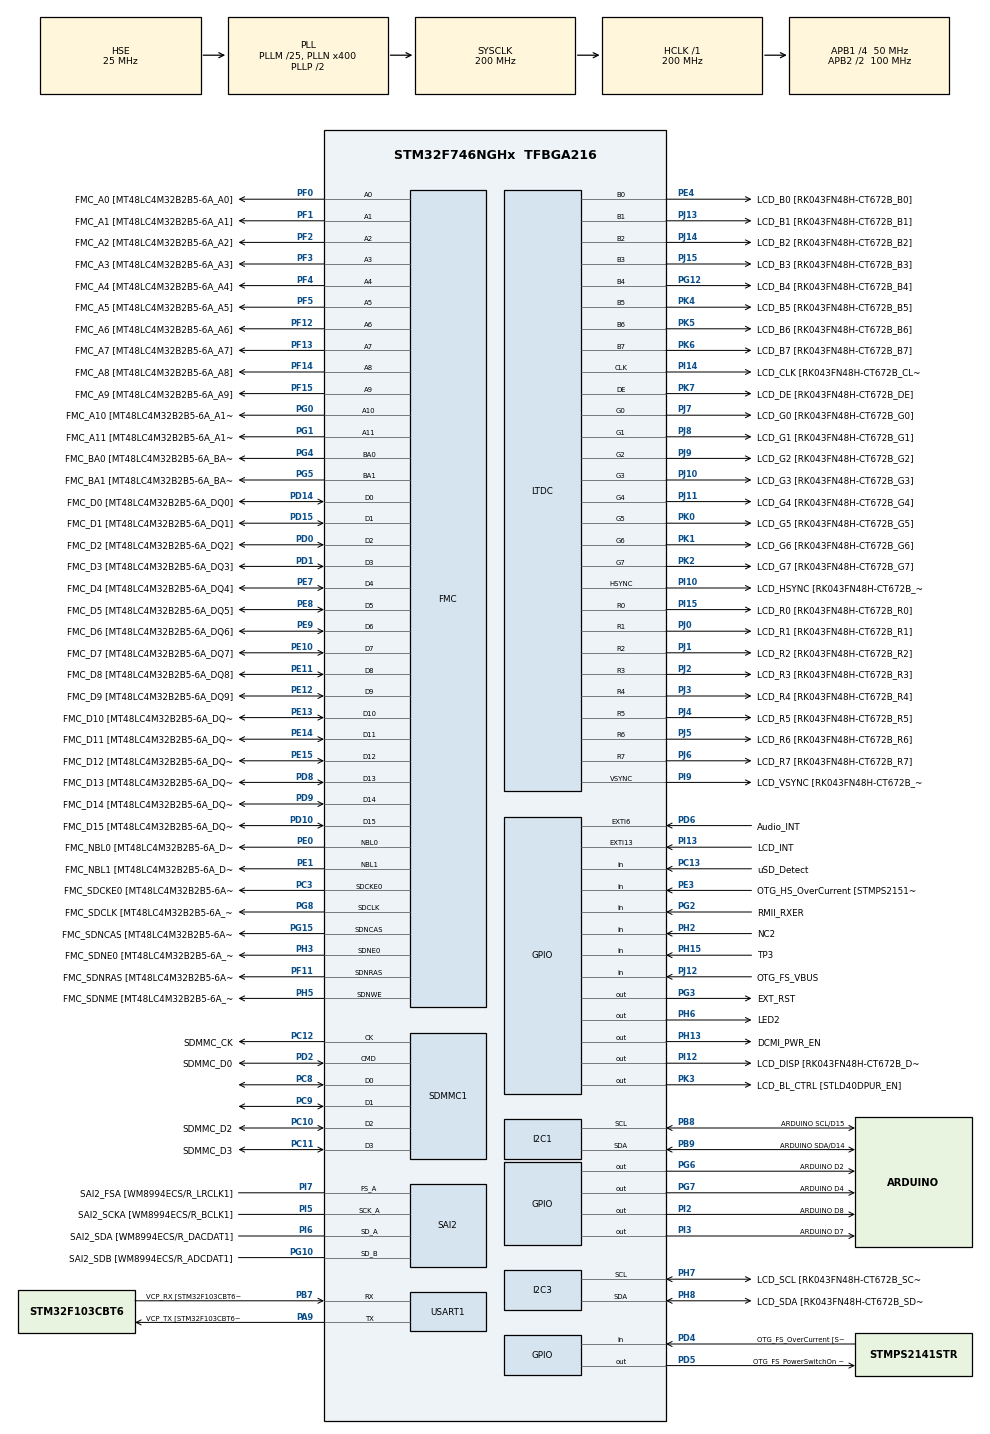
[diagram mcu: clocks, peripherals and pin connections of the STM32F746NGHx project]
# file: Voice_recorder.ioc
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PD12.GPIO_Label=QSPI_D1 [N25Q128A13EF840E_DQ1]
SH.FMC_A0.0=FMC_A0,12b-sda1
FATFS0.BSP.api=Unknown
PH15.GPIO_Label=TP3
NVIC.TIM6_DAC_IRQn=true\:0\:0\:false\:false\:true\:false\:false\:true
PG8.Signal=FMC_SDCLK
PG0.Signal=FMC_A10
PI15.GPIO_Label=LCD_R0 [RK043FN48H-CT672B_R0]
PK1.Signal=LTDC_G6
SH.FMC_D5_DA5.0=FMC_D5,sd-16b-d1
PF10.GPIO_PuPd=GPIO_NOPULL
SH.FMC_D9_DA9.0=FMC_D9,sd-16b-d1
PG15.GPIO_Label=FMC_SDNCAS [MT48LC4M32B2B5-6A_CAS]
PF7.Signal=ADC3_IN5
RCC.PLL48CLockSelection=RCC_CLK48SOURCE_PLLSAIP
SH.FMC_SDNWE.0=FMC_SDNWE,12b-sda1
PH9.Signal=DCMI_D0
SH.FMC_D11_DA11.0=FMC_D11,sd-16b-d1
PJ5.Mode=RGB888
RCC.APB2TimFreq_Value=200000000
PB6.Signal=QUADSPI_BK1_NCS
PC7.Signal=USART6_RX
PD0.Signal=FMC_D2_DA2
PD8.Signal=FMC_D13_DA13
PE1.Signal=FMC_NBL1
FATFS0.BSP.ip=GPIO
Dma.SAI2_B.3.Mode=DMA_CIRCULAR
PF1.GPIO_Label=FMC_A1 [MT48LC4M32B2B5-6A_A1]
PI4.GPIO_Label=SAI2_MCLKA [WM8994ECS/R_MCLK1]
PK4.GPIO_Label=LCD_B5 [RK043FN48H-CT672B_B5]
PD1.GPIO_Label=FMC_D3 [MT48LC4M32B2B5-6A_DQ3]
PB12.GPIO_Label=ULPI_D5 [USB3320C-EZK_D5]
PJ14.Mode=RGB888
PF12.GPIO_Label=FMC_A6 [MT48LC4M32B2B5-6A_A6]
LTDC.PixelFormat_L0=LTDC_PIXEL_FORMAT_RGB565
LTDC.PixelFormat_L1=LTDC_PIXEL_FORMAT_RGB565
SAI2.Instance-SAI_B_SyncSlave=SAI$Index_Block_B
PC4.GPIO_Label=RMII_RXD0 [LAN8742A-CZ-TR_RXD0]
PE9.Signal=FMC_D6_DA6
SH.FMC_A2.0=FMC_A2,12b-sda1
PB1.GPIO_Label=ULPI_D2 [USB3320C-EZK_D2]
PE4.GPIO_Label=LCD_B0 [RK043FN48H-CT672B_B0]
PG4.GPIO_Label=FMC_BA0 [MT48LC4M32B2B5-6A_BA0]
PC9.Mode=SD_4_bits_Wide_bus
PA8.Signal=S_TIM1_CH1
SH.FMC_D1_DA1.0=FMC_D1,sd-16b-d1
VP_FREERTOS_VS_CMSIS_V1.Mode=CMSIS_V1
LTDC.HSync=41
PJ14.Signal=LTDC_B2
Dma.SAI2_A.2.Priority=DMA_PRIORITY_LOW
PB9.Signal=I2C1_SDA
Mcu.Package=TFBGA216
PB1.Signal=USB_OTG_HS_ULPI_D2
PB14.GPIO_PuPd=GPIO_NOPULL
Dma.SAI2_B.3.Instance=DMA2_Stream7
NVIC.TimeBase=TIM6_DAC_IRQn
PD12.Signal=QUADSPI_BK1_IO1
NVIC.TimeBaseIP=TIM6
PB9.GPIO_PuPd=GPIO_NOPULL
PA10.Signal=USB_OTG_FS_ID
PE12.GPIO_Label=FMC_D9 [MT48LC4M32B2B5-6A_DQ9]
PC11.Mode=SD_4_bits_Wide_bus
RCC.APB2CLKDivider=RCC_HCLK_DIV2
PI7.Mode=SAI_A_Master
LTDC.VSync=10
RCC.APB1TimFreq_Value=100000000
PC14/OSC32_IN.GPIO_Label=RCC_OSC32_IN
PJ13.Mode=RGB888
PH8.Mode=I2C
PF9.GPIO_PuPd=GPIO_NOPULL
Dma.SDMMC1_RX.0.Mode=DMA_PFCTRL
PA4.GPIO_Label=DCMI_HSYNC
PA8.GPIO_Speed=GPIO_SPEED_FREQ_LOW
PD15.Signal=FMC_D1_DA1
PJ1.GPIO_Label=LCD_R2 [RK043FN48H-CT672B_R2]
PG12.Signal=LTDC_B4
Dma.SAI2_B.3.FIFOMode=DMA_FIFOMODE_DISABLE
FATFS0.BSP.STBoard=false
PK4.Signal=LTDC_B5
SH.FMC_A4.0=FMC_A4,12b-sda1
FREERTOS.Tasks01=defaultTask,-3,128,StartDefaultTask,Default,NULL,Dynamic,NULL,NULL;SD,0,20000,SDTask,Default,NULL,Dynamic,NULL,NULL;Audio,0,2048,AudioTask,Default,NULL,Dynamic,NULL,NULL;input,0,1024,InputTask,Default,NULL,Dynamic,NULL,NULL
Dma.SDMMC1_RX.0.PeriphInc=DMA_PINC_DISABLE
PH13.Signal=GPIO_Output
PI13.GPIO_ModeDefaultEXTI=GPIO_MODE_EVT_RISING
PG5.Signal=FMC_A15_BA1
PC13.Signal=GPIO_Input
SH.FMC_D10_DA10.0=FMC_D10,sd-16b-d1
FATFS0.BSP.mode=Input
FREERTOS.INCLUDE_vTaskDelayUntil=1
PD3.Signal=DCMI_D5
PI10.Mode=RGB888
PC2.Signal=USB_OTG_HS_ULPI_DIR
PI12.Signal=GPIO_Output
LTDC.ImageWidth_L1=480
Dma.SAI2_A.2.MemInc=DMA_MINC_ENABLE
PJ11.Signal=LTDC_G4
RCC.PLLSAIRDiv=RCC_PLLSAIDIVR_8
PF8.GPIO_Label=ARDUINO A3
LTDC.ImageWidth_L0=480
PD10.Signal=FMC_D15_DA15
PJ6.Mode=RGB888
PB8.GPIO_Label=ARDUINO SCL/D15
PJ8.GPIO_Label=LCD_G1 [RK043FN48H-CT672B_G1]
PJ3.Signal=LTDC_R4
PI8.GPIO_Label=NC1 [TP2]
PA8.GPIO_Label=ARDUINO PWM/D10
CORTEX_M7.ART_ACCLERATOR_ENABLE=1
PE8.GPIO_Label=FMC_D5 [MT48LC4M32B2B5-6A_DQ5]
PH11.GPIO_Label=DCMI_D2
PI6.Mode=SAI_A_Master
NVIC.DMA2_Stream6_IRQn=true\:5\:0\:false\:false\:true\:true\:false\:true
PJ11.GPIO_Label=LCD_G4 [RK043FN48H-CT672B_G4]
PB14.Signal=SPI2_MISO
PA5.Signal=USB_OTG_HS_ULPI_CK
PC12.Mode=SD_4_bits_Wide_bus
PF10.GPIO_Mode=GPIO_MODE_ANALOG
PJ4.GPIO_Label=LCD_R5 [RK043FN48H-CT672B_R5]
PE1.GPIO_Label=FMC_NBL1 [MT48LC4M32B2B5-6A_DQM1]
PK7.GPIO_Label=LCD_DE [RK043FN48H-CT672B_DE]
PI7.Signal=SAI2_FS_A
SH.FMC_A6.0=FMC_A6,12b-sda1
PE14.Signal=FMC_D11_DA11
LTDC.Blue_L1=0
LTDC.Blue_L0=255
PB4.GPIO_Label=ARDUINO PWM/D3
PB15.GPIO_Label=ARDUINO MOSI/PWM/D11
PG7.GPIO_Label=ARDUINO D4
PI2.Signal=GPIO_Output
PF4.GPIO_Label=FMC_A4 [MT48LC4M32B2B5-6A_A4]
PA1.GPIO_Label=RMII_REF_CLK [LAN8742A-CZ-TR_REFCLK0]
PF13.Signal=FMC_A7
Dma.SAI2_A.2.PeriphInc=DMA_PINC_DISABLE
PA0/WKUP.GPIO_PuPd=GPIO_NOPULL
PJ15.GPIO_Label=LCD_B3 [RK043FN48H-CT672B_B3]
NVIC.DMA2_Stream4_IRQn=true\:5\:0\:false\:false\:true\:true\:false\:true
PC7.GPIO_Label=ARDUINO RX/D0
PC8.Mode=SD_4_bits_Wide_bus
PJ15.Mode=RGB888
PA5.GPIO_Label=ULPI_CLK [USB3320C-EZK_CLKOUT]
PK4.Mode=RGB888
PC12.GPIO_Label=SDMMC_CK
PE5.GPIO_Label=DCMI_D6
Dma.SDMMC1_TX.1.PeriphDataAlignment=DMA_PDATAALIGN_WORD
PJ8.Signal=LTDC_G1
PJ0.GPIO_Label=LCD_R1 [RK043FN48H-CT672B_R1]
ProjectManager.HeapSize=0x400
PH6.Signal=GPIO_Output
NVIC.PriorityGroup=NVIC_PRIORITYGROUP_4
PF0.GPIO_Label=FMC_A0 [MT48LC4M32B2B5-6A_A0]
PI1.GPIO_Mode=GPIO_MODE_AF_PP
PE3.Signal=GPIO_Input
PJ4.Mode=RGB888
PC15/OSC32_OUT.Signal=RCC_OSC32_OUT
PF4.Signal=FMC_A4
PD2.Signal=SDMMC1_CMD
FATFS0.BSP.name=Detect_SDIO
PI1.GPIO_Label=ARDUINO SCK/D13
Mcu.Family=STM32F7
LTDC.BlendingFactor1_L1=LTDC_BLENDING_FACTOR1_PAxCA
LTDC.BlendingFactor1_L0=LTDC_BLENDING_FACTOR1_PAxCA
PK3.Signal=GPIO_Output
SH.FMC_A8.0=FMC_A8,12b-sda1
PC15/OSC32_OUT.GPIO_Label=RCC_OSC32_OUT
PH14.Signal=DCMI_D4
PH10.Signal=DCMI_D1
SH.FMC_D14_DA14.0=FMC_D14,sd-16b-d1
PG2.Signal=GPIO_Input
PE11.GPIO_Label=FMC_D8 [MT48LC4M32B2B5-6A_DQ8]
PD0.GPIO_Label=FMC_D2 [MT48LC4M32B2B5-6A_DQ2]
PC14/OSC32_IN.Mode=LSE-External-Oscillator
SH.FMC_A14_BA0.0=FMC_BA0,FourSdramBanks1
SH.FMC_A11.0=FMC_A11,12b-sda1
Dma.SDMMC1_RX.0.Instance=DMA2_Stream3
Dma.SDMMC1_RX.0.FIFOMode=DMA_FIFOMODE_ENABLE
PB13.GPIO_Label=ULPI_D6 [USB3320C-EZK_D6]
PG5.GPIO_Label=FMC_BA1 [MT48LC4M32B2B5-6A_BA1]
PI5.Mode=SAI_A_Master
PB15.Signal=SPI2_MOSI
PG15.Signal=FMC_SDNCAS
PG11.Signal=ETH_TX_EN
PJ5.GPIO_Label=LCD_R6 [RK043FN48H-CT672B_R6]
PJ14.GPIO_Label=LCD_B2 [RK043FN48H-CT672B_B2]
SAI2.RealAudioFreq-SAI_A_Master=46.875 KHz
PD13.Signal=QUADSPI_BK1_IO3
PA15.GPIO_Label=ARDUINO PWM/D9
PJ2.Signal=LTDC_R3
LTDC.WindowX1_L1=480
SH.FMC_NBL1.0=FMC_NBL1,Sd2ByteEnable1
LTDC.WindowX1_L0=480
PI9.Mode=RGB888
PK2.Mode=RGB888
PA15.GPIO_ModeDefaultPP=GPIO_MODE_AF_PP
PA9.GPIO_Mode=GPIO_MODE_AF_PP
RCC.HSE_VALUE=25000000
PF7.GPIO_Mode=GPIO_MODE_ANALOG
PI14.Mode=RGB888
PF8.GPIO_PuPd=GPIO_NOPULL
PA14.Mode=Serial_Wire
PH7.GPIO_Label=LCD_SCL [RK043FN48H-CT672B_SCL]
PJ7.GPIO_Label=LCD_G0 [RK043FN48H-CT672B_G0]
PF11.Signal=FMC_SDNRAS
Dma.SAI2_A.2.PeriphDataAlignment=DMA_PDATAALIGN_HALFWORD
PC11.GPIO_Label=SDMMC_D3
LTDC.Red_L0=255
LTDC.Red_L1=0
PJ12.GPIO_Label=OTG_FS_VBUS
PB7.Signal=USART1_RX
SH.S_TIM3_CH1.0=TIM3_CH1
PB7.GPIO_Label=VCP_RX [STM32F103CBT6_PA2]
PD13.GPIO_Label=QSPI_D3 [N25Q128A13EF840E_DQ3]
PA6.Signal=DCMI_PIXCLK
PB15.GPIO_PuPd=GPIO_NOPULL
PD5.GPIO_Label=OTG_FS_PowerSwitchOn [STMPS2141STR_EN]
PA15.Signal=S_TIM2_CH1_ETR
PF8.Signal=ADC3_IN6
PG0.GPIO_Label=FMC_A10 [MT48LC4M32B2B5-6A_A10]
PI0.GPIO_Label=ARDUINO PWM/CS/D5
PA0/WKUP.GPIO_Mode=GPIO_MODE_ANALOG
I2C3.Timing=0x00C0EAFF
PB5.GPIO_Label=ULPI_D7 [USB3320C-EZK_D7]
Dma.Request2=SAI2_A
Dma.Request1=SDMMC1_TX
Dma.Request3=SAI2_B
PG11.GPIO_Label=RMII_TX_EN [LAN8742A-CZ-TR_TXEN]
PD3.GPIO_Label=DCMI_D5
PC5.Signal=ETH_RXD1
PE7.Signal=FMC_D4_DA4
PD6.Signal=GPXTI6
Dma.Request0=SDMMC1_RX
PF3.GPIO_Label=FMC_A3 [MT48LC4M32B2B5-6A_A3]
Dma.SDMMC1_RX.0.MemDataAlignment=DMA_MDATAALIGN_WORD
PI15.Mode=RGB888
PE2.GPIO_Label=QSPI_D2 [N25Q128A13EF840E_DQ2]
PB4.Signal=S_TIM3_CH1
PG2.GPIO_Label=RMII_RXER
PA3.Signal=USB_OTG_HS_ULPI_D0
PK1.Mode=RGB888
PK6.Signal=LTDC_B7
NVIC.LTDC_IRQn=true\:5\:0\:false\:false\:true\:true\:true\:true
PD15.GPIO_Label=FMC_D1 [MT48LC4M32B2B5-6A_DQ1]
LTDC.WindowY1_L0=272
PG7.Signal=GPIO_Output
LTDC.WindowY1_L1=272
PJ8.Mode=RGB888
PH12.GPIO_Label=DCMI_D3
PC11.Signal=SDMMC1_D3
PI14.Signal=LTDC_CLK
PC8.Signal=SDMMC1_D0
PC10.Mode=SD_4_bits_Wide_bus
PE14.GPIO_Label=FMC_D11 [MT48LC4M32B2B5-6A_DQ11]
PD9.Signal=FMC_D14_DA14
SAI2.Instance-SAI_A_Master=SAI$Index_Block_A
PA9.GPIO_PuPd=GPIO_NOPULL
PA12.GPIO_Label=OTG_FS_P
PD8.GPIO_Label=FMC_D13 [MT48LC4M32B2B5-6A_DQ13]
FATFS0.BSP.instance=PC13
PG8.GPIO_Label=FMC_SDCLK [MT48LC4M32B2B5-6A_CLK]
USART1.VirtualMode-Asynchronous=VM_ASYNC
PA13.Signal=SYS_JTMS-SWDIO
FREERTOS.configUSE_IDLE_HOOK=1
PA9.Mode=Asynchronous
SH.S_TIM1_CH1.0=TIM1_CH1
PF6.Signal=ADC3_IN4
PB10.GPIO_Label=ULPI_D3 [USB3320C-EZK_D3]
SH.FMC_D13_DA13.0=FMC_D13,sd-16b-d1
PH8.Signal=I2C3_SDA
PB9.Mode=I2C
RCC.USBFreq_Value=48000000
PF9.GPIO_Label=ARDUINO A2
PD10.GPIO_Label=FMC_D15 [MT48LC4M32B2B5-6A_DQ15]
Dma.SAI2_B.3.Direction=DMA_PERIPH_TO_MEMORY
PA1.Signal=ETH_REF_CLK
Dma.SAI2_A.2.MemDataAlignment=DMA_MDATAALIGN_HALFWORD
PD2.Mode=SD_4_bits_Wide_bus
PK5.Mode=RGB888
board=STM32F746G-DISCO
PG12.Mode=RGB888
RCC.VCOOutputFreq_Value=400000000
PI9.Signal=LTDC_VSYNC
PH4.GPIO_Label=ULPI_NXT [USB3320C-EZK_NXT]
PI13.GPIO_Label=LCD_INT
PI4.Signal=SAI2_MCLK_A
PC1.GPIO_Label=RMII_MDC [LAN8742A-CZ-TR_MDC]
SH.FMC_D12_DA12.0=FMC_D12,sd-16b-d1
PF15.GPIO_Label=FMC_A9 [MT48LC4M32B2B5-6A_A9]
Dma.SDMMC1_RX.0.MemBurst=DMA_MBURST_INC4
PI1.GPIO_Speed=GPIO_SPEED_FREQ_LOW
PF1.Signal=FMC_A1
PF8.GPIO_Mode=GPIO_MODE_ANALOG
PJ0.Signal=LTDC_R1
PE0.Signal=FMC_NBL0
PE7.GPIO_Label=FMC_D4 [MT48LC4M32B2B5-6A_DQ4]
PE12.Signal=FMC_D9_DA9
RCC.SYSCLKFreq_VALUE=200000000
Dma.SDMMC1_TX.1.MemBurst=DMA_MBURST_INC4
PJ5.Signal=LTDC_R6
PA15.GPIO_Speed=GPIO_SPEED_FREQ_LOW
RCC.HSI_VALUE=16000000
PA8.GPIO_PuPd=GPIO_NOPULL
PH0/OSC_IN.GPIO_Label=OSC_25M [NZ2520SB-25.00M_OUT]
PF9.GPIO_Mode=GPIO_MODE_ANALOG
RCC.PLLQ=9
PI3.GPIO_Label=ARDUINO D7
PH3.Signal=FMC_SDNE0
RCC.PLLM=25
RCC.PLLN=400
PA9.GPIO_Speed=GPIO_SPEED_FREQ_LOW
CORTEX_M7.CPU_DCache=Enabled
PB8.GPIO_Speed=GPIO_SPEED_FREQ_LOW
PJ2.GPIO_Label=LCD_R3 [RK043FN48H-CT672B_R3]
LTDC.ImageHeight_L0=272
PB14.GPIO_Mode=GPIO_MODE_AF_PP
LTDC.ImageHeight_L1=140
Dma.SDMMC1_TX.1.PeriphInc=DMA_PINC_DISABLE
RCC.PLLI2SN=100
PB12.Signal=USB_OTG_HS_ULPI_D5
PJ13.Signal=LTDC_B1
PK1.GPIO_Label=LCD_G6 [RK043FN48H-CT672B_G6]
PA3.GPIO_Label=ULPI_D0 [USB3320C-EZK_D0]
SH.FMC_D7_DA7.0=FMC_D7,sd-16b-d1
PK5.Signal=LTDC_B6
PB15.GPIO_Mode=GPIO_MODE_AF_PP
VP_SYS_VS_tim6.Mode=TIM6
SAI2.ErrorAudioFreq-SAI_A_Master=-2.34 %
PJ9.Mode=RGB888
PH12.Signal=DCMI_D3
Dma.SDMMC1_RX.0.MemInc=DMA_MINC_ENABLE
VP_FATFS_VS_SDIO.Mode=SDIO
PK0.Mode=RGB888
PG4.Signal=FMC_A14_BA0
PC12.Signal=SDMMC1_CK
PB14.GPIO_Label=ARDUINO MISO/D12
PA14.GPIO_Label=SWCLK
PG6.GPIO_Label=ARDUINO D2
PH6.GPIO_Label=LED2
PK6.GPIO_Label=LCD_B7 [RK043FN48H-CT672B_B7]
PC6.GPIO_Label=ARDUINO TX/D1
PI6.GPIO_Label=SAI2_SDA [WM8994ECS/R_DACDAT1]
PB6.GPIO_Label=QSPI_NCS [N25Q128A13EF840E_S]
PJ6.GPIO_Label=LCD_R7 [RK043FN48H-CT672B_R7]
PB13.Signal=USB_OTG_HS_ULPI_D6
PD6.GPIO_Label=Audio_INT
PG13.Signal=ETH_TXD0
PE6.GPIO_Label=DCMI_D7
PF6.GPIO_Label=ARDUINO A5
RCC.SYSCLKSource=RCC_SYSCLKSOURCE_PLLCLK
PJ10.Signal=LTDC_G3
SH.FMC_A15_BA1.0=FMC_BA1,FourSdramBanks1
NVIC.SDMMC1_IRQn=true\:5\:0\:false\:false\:true\:true\:true\:true
PB7.GPIO_Mode=GPIO_MODE_AF_PP
PJ13.GPIO_Label=LCD_B1 [RK043FN48H-CT672B_B1]
PI0.GPIO_PuPd=GPIO_NOPULL
PH5.Signal=FMC_SDNWE
Dma.SAI2_A.2.Mode=DMA_CIRCULAR
PD4.Signal=GPIO_Input
PH1/OSC_OUT.Signal=RCC_OSC_OUT
PC3.Signal=FMC_SDCKE0
PE5.Signal=DCMI_D6
PF10.GPIO_Label=ARDUINO A1
PH10.GPIO_Label=DCMI_D1
FATFS0.BSP.i2caddr=0
PK7.Mode=RGB888
PJ2.Mode=RGB888
PI6.Signal=SAI2_SD_A
PI3.Signal=GPIO_Output
PE2.Signal=QUADSPI_BK1_IO2
SAI2.AudioFrequency-SAI_A_Master=SAI_AUDIO_FREQUENCY_48K
PF3.Signal=FMC_A3
PE10.Signal=FMC_D7_DA7
RCC.SDMMCClockSelection=RCC_SDMMC1CLKSOURCE_CLK48
PD6.GPIO_ModeDefaultEXTI=GPIO_MODE_EVT_RISING
FATFS0.BSP.solution=PC13
Dma.SDMMC1_RX.0.PeriphBurst=DMA_PBURST_INC4
PJ4.Signal=LTDC_R5
SH.FMC_A1.0=FMC_A1,12b-sda1
PH2.Signal=GPIO_Input
SH.FMC_SDCLK.0=FMC_SDCLK,12b-sda1
PF14.Signal=FMC_A8
VP_DMA2D_VS_DMA2D.Mode=DMA2D_Activate
PF6.GPIO_Mode=GPIO_MODE_ANALOG
Dma.SDMMC1_TX.1.MemInc=DMA_MINC_ENABLE
PE10.GPIO_Label=FMC_D7 [MT48LC4M32B2B5-6A_DQ7]
PJ1.Mode=RGB888
SH.FMC_D3_DA3.0=FMC_D3,sd-16b-d1
PI10.GPIO_Label=LCD_HSYNC [RK043FN48H-CT672B_HSYNC]
Dma.SAI2_A.2.Direction=DMA_MEMORY_TO_PERIPH
PB7.GPIO_PuPd=GPIO_NOPULL
Dma.SDMMC1_TX.1.Instance=DMA2_Stream6
PH15.Signal=GPIO_Input
PD9.GPIO_Label=FMC_D14 [MT48LC4M32B2B5-6A_DQ14]
PG9.Signal=DCMI_VSYNC
PA9.GPIO_Label=VCP_TX [STM32F103CBT6_PA3]
FREERTOS.configCHECK_FOR_STACK_OVERFLOW=2
PB8.GPIO_PuPd=GPIO_NOPULL
PC6.Signal=USART6_TX
PB11.GPIO_Label=ULPI_D4 [USB3320C-EZK_D4]
PD7.Signal=SPDIFRX_IN0
PD1.Signal=FMC_D3_DA3
PA11.GPIO_Label=OTG_FS_N
PF14.GPIO_Label=FMC_A8 [MT48LC4M32B2B5-6A_A8]
Dma.SDMMC1_RX.0.PeriphDataAlignment=DMA_PDATAALIGN_WORD
PC0.Signal=USB_OTG_HS_ULPI_STP
RCC.APB1CLKDivider=RCC_HCLK_DIV4
PF13.GPIO_Label=FMC_A7 [MT48LC4M32B2B5-6A_A7]
PG13.GPIO_Label=RMII_TXD0 [LAN8742A-CZ-TR_TXD0]
Dma.SAI2_B.3.Priority=DMA_PRIORITY_LOW
PG10.Signal=SAI2_SD_B
SH.FMC_A3.0=FMC_A3,12b-sda1
PJ7.Signal=LTDC_G0
PI0.GPIO_Speed=GPIO_SPEED_FREQ_LOW
PB14.GPIO_Speed=GPIO_SPEED_FREQ_LOW
SH.FMC_D15_DA15.0=FMC_D15,sd-16b-d1
PA9.Signal=USART1_TX
I2C1.Timing=0x00C0EAFF
SAI2.VirtualMode-SAI_B_SyncSlave=VM_SLAVE
PB4.GPIO_PuPd=GPIO_NOPULL
PE9.GPIO_Label=FMC_D6 [MT48LC4M32B2B5-6A_DQ6]
PB10.Signal=USB_OTG_HS_ULPI_D3
FATFS.BSP.number=1
PJ15.Signal=LTDC_B3
PH9.GPIO_Label=DCMI_D0
PI9.GPIO_Label=LCD_VSYNC [RK043FN48H-CT672B_VSYNC]
PA8.GPIO_ModeDefaultPP=GPIO_MODE_AF_PP
PE15.Signal=FMC_D12_DA12
PE8.Signal=FMC_D5_DA5
PI1.Signal=SPI2_SCK
Dma.SDMMC1_RX.0.Direction=DMA_PERIPH_TO_MEMORY
PA0/WKUP.GPIO_Label=ARDUINO A0
Dma.SDMMC1_TX.1.FIFOMode=DMA_FIFOMODE_ENABLE
PG14.GPIO_Label=RMII_TXD1 [LAN8742A-CZ-TR_TXD1]
PA13.Mode=Serial_Wire
SH.FMC_SDNCAS.0=FMC_SDNCAS,12b-sda1
SAI2.MClockEnable-SAI_A_Master=SAI_MASTERCLOCK_DISABLE
PF7.GPIO_PuPd=GPIO_NOPULL
PH14.GPIO_Label=DCMI_D4
PA4.Signal=DCMI_HSYNC
PB5.Signal=USB_OTG_HS_ULPI_D7
PE13.GPIO_Label=FMC_D10 [MT48LC4M32B2B5-6A_DQ10]
PD11.Signal=QUADSPI_BK1_IO0
LTDC.Alpha_L1=255
SH.FMC_A5.0=FMC_A5,12b-sda1
LTDC.Alpha_L0=255
PA11.Signal=USB_OTG_FS_DM
SH.S_TIM2_CH1_ETR.0=TIM2_CH1
PK3.GPIO_Label=LCD_BL_CTRL [STLD40DPUR_EN]
PF9.Signal=ADC3_IN7
PJ10.Mode=RGB888
FREERTOS.Mutexes01=mutex_LCD,Dynamic,NULL
PB8.Mode=I2C
PF6.GPIO_PuPd=GPIO_NOPULL
PC3.GPIO_Label=FMC_SDCKE0 [MT48LC4M32B2B5-6A_CKE]
PG3.GPIO_Label=EXT_RST
PB0.Signal=USB_OTG_HS_ULPI_D1
PC1.Signal=ETH_MDC
PG10.GPIO_Label=SAI2_SDB [WM8994ECS/R_ADCDAT1]
PD2.GPIO_Label=SDMMC_D0
PH2.GPIO_Label=NC2
PC3.Mode=SdramChipSelect1_1
PK7.Signal=LTDC_DE
RCC.CortexFreq_Value=200000000
PG6.Signal=GPIO_Output
LTDC.HBP=13
PC10.Signal=SDMMC1_D2
SH.FMC_NBL0.0=FMC_NBL0,Sd2ByteEnable1
PC0.GPIO_Label=ULPI_STP [USB3320C-EZK_STP]
SH.FMC_D6_DA6.0=FMC_D6,sd-16b-d1
PA0/WKUP.Signal=ADCx_IN0
PB0.GPIO_Label=ULPI_D1 [USB3320C-EZK_D1]
PH5.GPIO_Label=FMC_SDNME [MT48LC4M32B2B5-6A_WE]
PI5.GPIO_Label=SAI2_SCKA [WM8994ECS/R_BCLK1]
Dma.SDMMC1_RX.0.Priority=DMA_PRIORITY_LOW
PC13.GPIO_Label=uSD_Detect
PK5.GPIO_Label=LCD_B6 [RK043FN48H-CT672B_B6]
PB11.Signal=USB_OTG_HS_ULPI_D4
PI14.GPIO_Label=LCD_CLK [RK043FN48H-CT672B_CLK]
ProjectManager.StackSize=0x800
PH3.Mode=SdramChipSelect1_1
Dma.SDMMC1_TX.1.FIFOThreshold=DMA_FIFO_THRESHOLD_FULL
PJ6.Signal=LTDC_R7
SH.FMC_A7.0=FMC_A7,12b-sda1
PA12.Signal=USB_OTG_FS_DP
PH0/OSC_IN.Mode=HSE-External-Oscillator
PD11.GPIO_Label=QSPI_D0 [N25Q128A13EF840E_DQ0]
RCC.HCLKFreq_Value=200000000
PF11.GPIO_Label=FMC_SDNRAS [MT48LC4M32B2B5-6A_RAS]
PF12.Signal=FMC_A6
FREERTOS.configUSE_MALLOC_FAILED_HOOK=1
PI13.Signal=GPXTI13
SH.FMC_A10.0=FMC_A10,12b-sda1
RCC.AHBFreq_Value=200000000
SH.FMC_D8_DA8.0=FMC_D8,sd-16b-d1
Dma.SAI2_B.3.PeriphInc=DMA_PINC_DISABLE
PI8.Signal=RTC_TS
SH.FMC_D2_DA2.0=FMC_D2,sd-16b-d1
PE13.Signal=FMC_D10_DA10
PF7.GPIO_Label=ARDUINO A4
PI1.GPIO_PuPd=GPIO_NOPULL
Dma.SAI2_B.3.PeriphDataAlignment=DMA_PDATAALIGN_HALFWORD
PI5.Signal=SAI2_SCK_A
PK6.Mode=RGB888
PI0.Signal=S_TIM5_CH4
PA10.GPIO_Label=OTG_FS_ID
LTDC.HFP=32
LTDC.BlendingFactor2_L0=LTDC_BLENDING_FACTOR2_PAxCA
SH.ADCx_IN0.0=ADC3_IN0
LTDC.BlendingFactor2_L1=LTDC_BLENDING_FACTOR2_PAxCA
PE4.Mode=RGB888
SH.FMC_SDNRAS.0=FMC_SDNRAS,12b-sda1
LTDC.ActiveW=480
PE4.Signal=LTDC_B0
PH1/OSC_OUT.Mode=HSE-External-Oscillator
FREERTOS.configTOTAL_HEAP_SIZE=120000
PD7.GPIO_Label=SPDIF_RX0 [74LVC1G04SE_4]
PH7.Mode=I2C
PJ0.Mode=RGB888
NVIC.DMA2_Stream7_IRQn=true\:5\:0\:false\:false\:true\:true\:false\:true
PJ9.Signal=LTDC_G2
SH.FMC_D0_DA0.0=FMC_D0,sd-16b-d1
PJ12.Signal=GPIO_Input
PC14/OSC32_IN.Signal=RCC_OSC32_IN
PK0.GPIO_Label=LCD_G5 [RK043FN48H-CT672B_G5]
PA2.GPIO_Label=RMII_MDIO [LAN8742A-CZ-TR_MDIO]
PF5.GPIO_Label=FMC_A5 [MT48LC4M32B2B5-6A_A5]
SH.FMC_A9.0=FMC_A9,12b-sda1
PJ1.Signal=LTDC_R2
SH.FMC_D4_DA4.0=FMC_D4,sd-16b-d1
PI12.GPIO_Label=LCD_DISP [RK043FN48H-CT672B_DISP] 
PE0.GPIO_Label=FMC_NBL0 [MT48LC4M32B2B5-6A_DQM0]
RCC.PLLSAIN=384
PH3.GPIO_Label=FMC_SDNE0 [MT48LC4M32B2B5-6A_CS]
PF5.Signal=FMC_A5
RCC.PLLSAIP=RCC_PLLSAIP_DIV8
RCC.PLLSAIR=5
PH7.Signal=I2C3_SCL
PB9.GPIO_Speed=GPIO_SPEED_FREQ_LOW
PJ3.GPIO_Label=LCD_R4 [RK043FN48H-CT672B_R4]
PK2.GPIO_Label=LCD_G7 [RK043FN48H-CT672B_G7]
PJ7.Mode=RGB888
PF0.Signal=FMC_A0
PI2.GPIO_Label=ARDUINO D8
PC2.GPIO_Label=ULPI_DIR [USB3320C-EZK_DIR]
Dma.SDMMC1_TX.1.Direction=DMA_MEMORY_TO_PERIPH
PB7.GPIO_Speed=GPIO_SPEED_FREQ_LOW
PB3.GPIO_Label=SWO
RCC.PLLSourceVirtual=RCC_PLLSOURCE_HSE
PK2.Signal=LTDC_G7
LTDC.FBStartAdress_L0=0xC0000000
CORTEX_M7.CPU_ICache=Enabled
LTDC.FBStartAdress_L1=0xC001FE00
PB9.GPIO_Label=ARDUINO SDA/D14
PC10.GPIO_Label=SDMMC_D2
PH11.Signal=DCMI_D2
PG3.Signal=GPIO_Output
PG1.Signal=FMC_A11
Dma.SAI2_A.2.Instance=DMA2_Stream4
PG10.Mode=SAI_B_SyncSlave
PC4.Signal=ETH_RXD0
PI0.GPIO_ModeDefaultPP=GPIO_MODE_AF_PP
PI10.Signal=LTDC_HSYNC
PD5.Signal=GPIO_Output
PJ11.Mode=RGB888
PH13.GPIO_Label=DCMI_PWR_EN
PH8.GPIO_Label=LCD_SDA [RK043FN48H-CT672B_SDA]
Dma.SDMMC1_TX.1.PeriphBurst=DMA_PBURST_INC4
PE15.GPIO_Label=FMC_D12 [MT48LC4M32B2B5-6A_DQ12]
PH4.Signal=USB_OTG_HS_ULPI_NXT
ProjectManager.TargetToolchain=STM32CubeIDE
LTDC.ActiveH=272
PJ9.GPIO_Label=LCD_G2 [RK043FN48H-CT672B_G2]
PF2.Signal=FMC_A2
NVIC.DMA2_Stream3_IRQn=true\:5\:0\:false\:false\:true\:true\:false\:true
PE11.Signal=FMC_D8_DA8
PK0.Signal=LTDC_G5
Dma.SAI2_B.3.MemInc=DMA_MINC_ENABLE
PG9.GPIO_Label=DCMI_VSYNC
PG14.Signal=ETH_TXD1
PB4.GPIO_ModeDefaultPP=GPIO_MODE_AF_PP
PJ10.GPIO_Label=LCD_G3 [RK043FN48H-CT672B_G3]
PG1.GPIO_Label=FMC_A11 [MT48LC4M32B2B5-6A_A11]
Dma.SAI2_A.2.FIFOMode=DMA_FIFOMODE_DISABLE
PB9.GPIO_Mode=GPIO_MODE_AF_OD
PJ3.Mode=RGB888
FATFS.USE_DMA_CODE_SD=1
PH0/OSC_IN.Signal=RCC_OSC_IN
PB4.GPIO_Speed=GPIO_SPEED_FREQ_LOW
RCC.APB2Freq_Value=100000000
LTDC.Layers=1
PD4.GPIO_Label=OTG_FS_OverCurrent [STMPS2141STR_Fault]
PF10.Signal=ADC3_IN8
PB15.GPIO_Speed=GPIO_SPEED_FREQ_LOW
SAI2.VirtualMode-SAI_A_Master=VM_MASTER
PI7.GPIO_Label=SAI2_FSA [WM8994ECS/R_LRCLK1]
SH.S_TIM5_CH4.0=TIM5_CH4
PF15.Signal=FMC_A9
PD14.GPIO_Label=FMC_D0 [MT48LC4M32B2B5-6A_DQ0]
Dma.SDMMC1_TX.1.Priority=DMA_PRIORITY_LOW
PD5.PinState=GPIO_PIN_SET
PE6.Signal=DCMI_D7
Mcu.Name=STM32F746NGHx
PA13.GPIO_Label=SWDIO
PA2.Signal=ETH_MDIO
LTDC.WindowY0_L1=132
PD14.Signal=FMC_D0_DA0
PB3.Signal=SYS_JTDO-SWO
Dma.SAI2_B.3.MemDataAlignment=DMA_MDATAALIGN_HALFWORD
PA7.GPIO_Label=RMII_CRS_DV [LAN8742A-CZ-TR_CRS_DV]
LTDC.Green_L1=0
PC5.GPIO_Label=RMII_RXD1 [LAN8742A-CZ-TR_RXD1]
Dma.SDMMC1_RX.0.FIFOThreshold=DMA_FIFO_THRESHOLD_FULL
PC15/OSC32_OUT.Mode=LSE-External-Oscillator
PB7.Mode=Asynchronous
LTDC.Green_L0=255
PA14.Signal=SYS_JTCK-SWCLK
PG12.GPIO_Label=LCD_B4 [RK043FN48H-CT672B_B4]
Dma.SDMMC1_TX.1.MemDataAlignment=DMA_MDATAALIGN_WORD
PA15.GPIO_PuPd=GPIO_NOPULL
PI15.Signal=LTDC_R0
PB8.Signal=I2C1_SCL
PE3.GPIO_Label=OTG_HS_OverCurrent [STMPS2151STR_FAULT]
PC9.Signal=SDMMC1_D1
PB8.GPIO_Mode=GPIO_MODE_AF_OD
RCC.APB1Freq_Value=50000000
Dma.SDMMC1_TX.1.Mode=DMA_PFCTRL
PA7.Signal=ETH_CRS_DV
PF2.GPIO_Label=FMC_A2 [MT48LC4M32B2B5-6A_A2]

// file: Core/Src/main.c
/* USER CODE BEGIN Header */
/**
 ******************************************************************************
 * @file           : main.c
 * @brief          : Main program body
 ******************************************************************************
 * @attention
 *
 * <h2><center>&copy; Copyright (c) 2021 STMicroelectronics.
 * All rights reserved.</center></h2>
 *
 * This software component is licensed by ST under BSD 3-Clause license,
 * the "License"; You may not use this file except in compliance with the
 * License. You may obtain a copy of the License at:
 *                        opensource.org/licenses/BSD-3-Clause
 *
 ******************************************************************************
 */
/* USER CODE END Header */
#include "main.h"
#include "cmsis_os.h"
#include "fatfs.h"

/* USER CODE BEGIN Includes */
#include "stm32746g_discovery_lcd.h"
#include "stm32746g_discovery_ts.h"
#include "stm32746g_discovery_audio.h"
#include "stdio.h"
#include "math.h"
#include <string.h>
/* USER CODE END Includes */

/* USER CODE BEGIN PD */

#define ARBG8888_BYTE_PER_PIXEL   4

// SDRAM
#define SDRAM_WRITE_READ_ADDR        ((uint32_t)(LCD_FB_START_ADDRESS + (RK043FN48H_WIDTH * RK043FN48H_HEIGHT * ARBG8888_BYTE_PER_PIXEL)))

#define SDRAM_WRITE_READ_ADDR_OFFSET ((uint32_t)0x0800)
#define SRAM_WRITE_READ_ADDR_OFFSET  SDRAM_WRITE_READ_ADDR_OFFSET

// Audio
#define AUDIO_REC_START_ADDR         SDRAM_WRITE_READ_ADDR

#define AUDIO_BLOCK_SIZE   	((uint32_t)512)
#define AUDIO_BUFFER_IN    	AUDIO_REC_START_ADDR     /* In SDRAM */
#define AUDIO_BUFFER_OUT   	(AUDIO_REC_START_ADDR + (AUDIO_BLOCK_SIZE*2)) /* In SDRAM */
#define AUDIO_BUFFER_R   	(AUDIO_REC_START_ADDR + (AUDIO_BLOCK_SIZE*4))
#define AUDIO_BUFFER_L   	(AUDIO_REC_START_ADDR + (AUDIO_BLOCK_SIZE*5))
#define AUDIO_POST  		(AUDIO_REC_START_ADDR + (AUDIO_BLOCK_SIZE*6))

// WAV File
#define Audio_freq 			AUDIO_FREQUENCY_16K
#define Audio_bit_res 		DEFAULT_AUDIO_IN_BIT_RESOLUTION
#define Audio_chan 			DEFAULT_AUDIO_IN_CHANNEL_NBR 	// A changer en mono
#define BytePerBloc			Audio_bit_res*Audio_chan/8
#define BytePerSec			BytePerBloc*Audio_freq

#define MASK_32_TO_8_0		0x000000FF
#define MASK_32_TO_8_1		0x0000FF00
#define MASK_32_TO_8_2		0x00FF0000
#define MASK_32_TO_8_3		0xFF000000

// Keyboard
#define MAJ					20
#define SPACE				'_'
#define BACKSPACE			8
#define ENTER				10

#define KEYBOARD_X 			0
#define KEYBOARD_Y			132

#define MAX_c 				30
/* USER CODE END PD */

DMA2D_HandleTypeDef hdma2d;

I2C_HandleTypeDef hi2c1;
I2C_HandleTypeDef hi2c3;

LTDC_HandleTypeDef hltdc;

SAI_HandleTypeDef hsai_BlockA2;
SAI_HandleTypeDef hsai_BlockB2;
DMA_HandleTypeDef hdma_sai2_a;
DMA_HandleTypeDef hdma_sai2_b;

SD_HandleTypeDef hsd1;
DMA_HandleTypeDef hdma_sdmmc1_rx;
DMA_HandleTypeDef hdma_sdmmc1_tx;

UART_HandleTypeDef huart1;

SDRAM_HandleTypeDef hsdram1;

osThreadId defaultTaskHandle;
osThreadId SDHandle;
osThreadId AudioHandle;
osThreadId inputHandle;
osMutexId mutex_LCDHandle;
/* USER CODE BEGIN PV */
osThreadId KBHandle;
uint8_t workBuffer[2 * _MAX_SS];

uint32_t  audio_rec_buffer_state;

typedef enum
{
	BUFFER_OFFSET_NONE = 0,
	BUFFER_OFFSET_HALF = 1,
	BUFFER_OFFSET_FULL = 2,
}BUFFER_StateTypeDef;

uint8_t Name[MAX_c] = "";
uint8_t keyboard[5][10] =	{
							{'1','2','3','4','5','6','7','8','9','0'},
							{'a','z','e','r','t','y','u','i','o','p'},
							{'q','s','d','f','g','h','j','k','l','m'},
							{MAJ,MAJ,'w','x','c','v','b','n',BACKSPACE,BACKSPACE},
							{0,0,SPACE,SPACE,SPACE,SPACE,SPACE,SPACE,ENTER,ENTER}
							};
/* USER CODE END PV */

void SystemClock_Config(void);
static void MX_GPIO_Init(void);
static void MX_DMA_Init(void);
static void MX_SDMMC1_SD_Init(void);
static void MX_FMC_Init(void);
static void MX_LTDC_Init(void);
static void MX_USART1_UART_Init(void);
static void MX_DMA2D_Init(void);
static void MX_SAI2_Init(void);
static void MX_I2C1_Init(void);
static void MX_I2C3_Init(void);
void StartDefaultTask(void const * argument);
void SDTask(void const * argument);
void AudioTask(void const * argument);
void InputTask(void const * argument);

/* USER CODE BEGIN PFP */
void write_header(uint32_t N_Bytes_Data);
void Draw_Keyboard(uint8_t MAJ_ENABLE);
void KeyboardTask(void const * argument);

void RL_sep(uint16_t* buffer, uint16_t size){
	uint16_t j=0,k=0;
	for(size_t i=0;i<size;i++){
		if(i%2){
			((uint16_t*)AUDIO_BUFFER_R)[j] = buffer[i];
			j++;
		}else{
			((uint16_t*)AUDIO_BUFFER_L)[k] = buffer[i];
			k++;
		}
	}
}

void RL_cat(uint16_t* buffer, uint16_t size){
	uint16_t j=0,k=0;
	for(size_t i=0;i<size;i++){
		if(i%2){
			buffer[i]=((uint16_t*)AUDIO_BUFFER_R)[j];
			j++;
		}
		else{
			buffer[i] = ((uint16_t*)AUDIO_BUFFER_L)[k];
			k++;
		}
	}
}

void treatment(){
	for(size_t i=0;i<AUDIO_BLOCK_SIZE/2;i++){
		((uint16_t*)AUDIO_POST)[i] = ((uint16_t*)AUDIO_BUFFER_L)[i] + ((uint16_t*)AUDIO_BUFFER_R)[i];
	}
}

void RL_cat2(uint16_t* buffer, uint16_t size){
	uint16_t j=0,k=0;
	for(size_t i=0;i<size;i++){
		if(i%2){
			buffer[i]=((uint16_t*)AUDIO_POST)[j];
			j++;
		}
		else{
			buffer[i] = ((uint16_t*)AUDIO_POST)[k];
			k++;
		}
	}
}
/* USER CODE END PFP */

int main(void)
{
  /* USER CODE BEGIN 1 */
	uint8_t status = 0;
  /* USER CODE END 1 */

  /* Enable I-Cache---------------------------------------------------------*/
  SCB_EnableICache();

  /* Enable D-Cache---------------------------------------------------------*/
  SCB_EnableDCache();

  /* MCU Configuration--------------------------------------------------------*/

  /* Reset of all peripherals, Initializes the Flash interface and the Systick. */
  HAL_Init();

  /* Configure the system clock */
  SystemClock_Config();

  /* Initialize all configured peripherals */
  MX_GPIO_Init();
  MX_DMA_Init();
  MX_SDMMC1_SD_Init();
  MX_FATFS_Init();
  MX_FMC_Init();
  MX_LTDC_Init();
  MX_USART1_UART_Init();
  MX_DMA2D_Init();
  MX_SAI2_Init();
  MX_I2C1_Init();
  MX_I2C3_Init();
  /* USER CODE BEGIN 2 */
  BSP_LCD_Init();
  BSP_LCD_LayerDefaultInit(0, LCD_FB_START_ADDRESS);
  BSP_LCD_LayerDefaultInit(1, LCD_FB_START_ADDRESS+ BSP_LCD_GetXSize()*BSP_LCD_GetYSize()*4);
  BSP_LCD_DisplayOn();
  BSP_LCD_SelectLayer(0);
  BSP_LCD_SetLayerVisible(0, ENABLE);
  BSP_LCD_SetLayerVisible(1, DISABLE);
  BSP_LCD_Clear(LCD_COLOR_WHITE);
  BSP_LCD_SetFont(&Font12);
  BSP_LCD_SetBackColor(LCD_COLOR_WHITE);
  BSP_LCD_SetTextColor(LCD_COLOR_LIGHTBLUE);

  status = BSP_TS_Init(BSP_LCD_GetXSize(), BSP_LCD_GetYSize());
  if (status != TS_OK){
	  BSP_LCD_SetBackColor(LCD_COLOR_WHITE);
	  BSP_LCD_SetTextColor(LCD_COLOR_RED);
	  BSP_LCD_DisplayStringAt(0, BSP_LCD_GetYSize() - 95, (uint8_t *)"ERROR", CENTER_MODE);
	  BSP_LCD_DisplayStringAt(0, BSP_LCD_GetYSize() - 80, (uint8_t *)"Touchscreen cannot be initialized", CENTER_MODE);
  } else {
	  BSP_LCD_DisplayStringAt(0, BSP_LCD_GetYSize() - 150, (uint8_t *)"TS initialized", CENTER_MODE);
  }
  /* USER CODE END 2 */

  /* Create the mutex(es) */
  /* definition and creation of mutex_LCD */
  osMutexDef(mutex_LCD);
  mutex_LCDHandle = osMutexCreate(osMutex(mutex_LCD));

  /* Create the thread(s) */
  /* definition and creation of defaultTask */
  osThreadDef(defaultTask, StartDefaultTask, osPriorityIdle, 0, 128);
  defaultTaskHandle = osThreadCreate(osThread(defaultTask), NULL);

  /* definition and creation of SD */
//  osThreadDef(SD, SDTask, osPriorityNormal, 0, 20000);
//  SDHandle = osThreadCreate(osThread(SD), NULL);

  /* definition and creation of Audio */
  osThreadDef(Audio, AudioTask, osPriorityNormal, 0, 2048);
  AudioHandle = osThreadCreate(osThread(Audio), NULL);

  /* definition and creation of input */
  osThreadDef(input, InputTask, osPriorityNormal, 0, 1024);
  inputHandle = osThreadCreate(osThread(input), NULL);

  /* Start scheduler */
  osKernelStart();

  /* We should never get here as control is now taken by the scheduler */
  /* Infinite loop */
	while (1)
	{

	}
}

void SystemClock_Config(void)
{
  RCC_OscInitTypeDef RCC_OscInitStruct = {0};
  RCC_ClkInitTypeDef RCC_ClkInitStruct = {0};
  RCC_PeriphCLKInitTypeDef PeriphClkInitStruct = {0};

  /** Configure LSE Drive Capability
  */
  HAL_PWR_EnableBkUpAccess();
  /** Configure the main internal regulator output voltage
  */
  __HAL_RCC_PWR_CLK_ENABLE();
  __HAL_PWR_VOLTAGESCALING_CONFIG(PWR_REGULATOR_VOLTAGE_SCALE1);
  /** Initializes the RCC Oscillators according to the specified parameters
  * in the RCC_OscInitTypeDef structure.
  */
  RCC_OscInitStruct.OscillatorType = RCC_OSCILLATORTYPE_HSE;
  RCC_OscInitStruct.HSEState = RCC_HSE_ON;
  RCC_OscInitStruct.PLL.PLLState = RCC_PLL_ON;
  RCC_OscInitStruct.PLL.PLLSource = RCC_PLLSOURCE_HSE;
  RCC_OscInitStruct.PLL.PLLM = 25;
  RCC_OscInitStruct.PLL.PLLN = 400;
  RCC_OscInitStruct.PLL.PLLP = RCC_PLLP_DIV2;
  RCC_OscInitStruct.PLL.PLLQ = 9;
  if (HAL_RCC_OscConfig(&RCC_OscInitStruct) != HAL_OK)
  {
    Error_Handler();
  }
  /** Activate the Over-Drive mode
  */
  if (HAL_PWREx_EnableOverDrive() != HAL_OK)
  {
    Error_Handler();
  }
  /** Initializes the CPU, AHB and APB buses clocks
  */
  RCC_ClkInitStruct.ClockType = RCC_CLOCKTYPE_HCLK|RCC_CLOCKTYPE_SYSCLK
                              |RCC_CLOCKTYPE_PCLK1|RCC_CLOCKTYPE_PCLK2;
  RCC_ClkInitStruct.SYSCLKSource = RCC_SYSCLKSOURCE_PLLCLK;
  RCC_ClkInitStruct.AHBCLKDivider = RCC_SYSCLK_DIV1;
  RCC_ClkInitStruct.APB1CLKDivider = RCC_HCLK_DIV4;
  RCC_ClkInitStruct.APB2CLKDivider = RCC_HCLK_DIV2;

  if (HAL_RCC_ClockConfig(&RCC_ClkInitStruct, FLASH_LATENCY_6) != HAL_OK)
  {
    Error_Handler();
  }
  PeriphClkInitStruct.PeriphClockSelection = RCC_PERIPHCLK_LTDC|RCC_PERIPHCLK_USART1
                              |RCC_PERIPHCLK_SAI2|RCC_PERIPHCLK_I2C1
                              |RCC_PERIPHCLK_I2C3|RCC_PERIPHCLK_SDMMC1
                              |RCC_PERIPHCLK_CLK48;
  PeriphClkInitStruct.PLLSAI.PLLSAIN = 384;
  PeriphClkInitStruct.PLLSAI.PLLSAIR = 5;
  PeriphClkInitStruct.PLLSAI.PLLSAIQ = 2;
  PeriphClkInitStruct.PLLSAI.PLLSAIP = RCC_PLLSAIP_DIV8;
  PeriphClkInitStruct.PLLSAIDivQ = 1;
  PeriphClkInitStruct.PLLSAIDivR = RCC_PLLSAIDIVR_8;
  PeriphClkInitStruct.Sai2ClockSelection = RCC_SAI2CLKSOURCE_PLLSAI;
  PeriphClkInitStruct.Usart1ClockSelection = RCC_USART1CLKSOURCE_PCLK2;
  PeriphClkInitStruct.I2c1ClockSelection = RCC_I2C1CLKSOURCE_PCLK1;
  PeriphClkInitStruct.I2c3ClockSelection = RCC_I2C3CLKSOURCE_PCLK1;
  PeriphClkInitStruct.Clk48ClockSelection = RCC_CLK48SOURCE_PLLSAIP;
  PeriphClkInitStruct.Sdmmc1ClockSelection = RCC_SDMMC1CLKSOURCE_CLK48;
  if (HAL_RCCEx_PeriphCLKConfig(&PeriphClkInitStruct) != HAL_OK)
  {
    Error_Handler();
  }
}

static void MX_DMA2D_Init(void)
{

  hdma2d.Instance = DMA2D;
  hdma2d.Init.Mode = DMA2D_M2M;
  hdma2d.Init.ColorMode = DMA2D_OUTPUT_ARGB8888;
  hdma2d.Init.OutputOffset = 0;
  hdma2d.LayerCfg[1].InputOffset = 0;
  hdma2d.LayerCfg[1].InputColorMode = DMA2D_INPUT_ARGB8888;
  hdma2d.LayerCfg[1].AlphaMode = DMA2D_NO_MODIF_ALPHA;
  hdma2d.LayerCfg[1].InputAlpha = 0;
  if (HAL_DMA2D_Init(&hdma2d) != HAL_OK)
  {
    Error_Handler();
  }
  if (HAL_DMA2D_ConfigLayer(&hdma2d, 1) != HAL_OK)
  {
    Error_Handler();
  }

}

static void MX_I2C1_Init(void)
{

  hi2c1.Instance = I2C1;
  hi2c1.Init.Timing = 0x00C0EAFF;
  hi2c1.Init.OwnAddress1 = 0;
  hi2c1.Init.AddressingMode = I2C_ADDRESSINGMODE_7BIT;
  hi2c1.Init.DualAddressMode = I2C_DUALADDRESS_DISABLE;
  hi2c1.Init.OwnAddress2 = 0;
  hi2c1.Init.OwnAddress2Masks = I2C_OA2_NOMASK;
  hi2c1.Init.GeneralCallMode = I2C_GENERALCALL_DISABLE;
  hi2c1.Init.NoStretchMode = I2C_NOSTRETCH_DISABLE;
  if (HAL_I2C_Init(&hi2c1) != HAL_OK)
  {
    Error_Handler();
  }
  /** Configure Analogue filter
  */
  if (HAL_I2CEx_ConfigAnalogFilter(&hi2c1, I2C_ANALOGFILTER_ENABLE) != HAL_OK)
  {
    Error_Handler();
  }
  /** Configure Digital filter
  */
  if (HAL_I2CEx_ConfigDigitalFilter(&hi2c1, 0) != HAL_OK)
  {
    Error_Handler();
  }

}

static void MX_I2C3_Init(void)
{

  hi2c3.Instance = I2C3;
  hi2c3.Init.Timing = 0x00C0EAFF;
  hi2c3.Init.OwnAddress1 = 0;
  hi2c3.Init.AddressingMode = I2C_ADDRESSINGMODE_7BIT;
  hi2c3.Init.DualAddressMode = I2C_DUALADDRESS_DISABLE;
  hi2c3.Init.OwnAddress2 = 0;
  hi2c3.Init.OwnAddress2Masks = I2C_OA2_NOMASK;
  hi2c3.Init.GeneralCallMode = I2C_GENERALCALL_DISABLE;
  hi2c3.Init.NoStretchMode = I2C_NOSTRETCH_DISABLE;
  if (HAL_I2C_Init(&hi2c3) != HAL_OK)
  {
    Error_Handler();
  }
  /** Configure Analogue filter
  */
  if (HAL_I2CEx_ConfigAnalogFilter(&hi2c3, I2C_ANALOGFILTER_ENABLE) != HAL_OK)
  {
    Error_Handler();
  }
  /** Configure Digital filter
  */
  if (HAL_I2CEx_ConfigDigitalFilter(&hi2c3, 0) != HAL_OK)
  {
    Error_Handler();
  }

}

static void MX_LTDC_Init(void)
{

  LTDC_LayerCfgTypeDef pLayerCfg = {0};
  LTDC_LayerCfgTypeDef pLayerCfg1 = {0};

  hltdc.Instance = LTDC;
  hltdc.Init.HSPolarity = LTDC_HSPOLARITY_AL;
  hltdc.Init.VSPolarity = LTDC_VSPOLARITY_AL;
  hltdc.Init.DEPolarity = LTDC_DEPOLARITY_AL;
  hltdc.Init.PCPolarity = LTDC_PCPOLARITY_IPC;
  hltdc.Init.HorizontalSync = 40;
  hltdc.Init.VerticalSync = 9;
  hltdc.Init.AccumulatedHBP = 53;
  hltdc.Init.AccumulatedVBP = 11;
  hltdc.Init.AccumulatedActiveW = 533;
  hltdc.Init.AccumulatedActiveH = 283;
  hltdc.Init.TotalWidth = 565;
  hltdc.Init.TotalHeigh = 285;
  hltdc.Init.Backcolor.Blue = 0;
  hltdc.Init.Backcolor.Green = 0;
  hltdc.Init.Backcolor.Red = 0;
  if (HAL_LTDC_Init(&hltdc) != HAL_OK)
  {
    Error_Handler();
  }
  pLayerCfg.WindowX0 = 0;
  pLayerCfg.WindowX1 = 480;
  pLayerCfg.WindowY0 = 0;
  pLayerCfg.WindowY1 = 272;
  pLayerCfg.PixelFormat = LTDC_PIXEL_FORMAT_RGB565;
  pLayerCfg.Alpha = 255;
  pLayerCfg.Alpha0 = 0;
  pLayerCfg.BlendingFactor1 = LTDC_BLENDING_FACTOR1_PAxCA;
  pLayerCfg.BlendingFactor2 = LTDC_BLENDING_FACTOR2_PAxCA;
  pLayerCfg.FBStartAdress = 0xC0000000;
  pLayerCfg.ImageWidth = 480;
  pLayerCfg.ImageHeight = 272;
  pLayerCfg.Backcolor.Blue = 255;
  pLayerCfg.Backcolor.Green = 255;
  pLayerCfg.Backcolor.Red = 255;
  if (HAL_LTDC_ConfigLayer(&hltdc, &pLayerCfg, 0) != HAL_OK)
  {
    Error_Handler();
  }
  pLayerCfg1.WindowX0 = 0;
  pLayerCfg1.WindowX1 = 480;
  pLayerCfg1.WindowY0 = 132;
  pLayerCfg1.WindowY1 = 272;
  pLayerCfg1.PixelFormat = LTDC_PIXEL_FORMAT_RGB565;
  pLayerCfg1.Alpha = 255;
  pLayerCfg1.Alpha0 = 0;
  pLayerCfg1.BlendingFactor1 = LTDC_BLENDING_FACTOR1_PAxCA;
  pLayerCfg1.BlendingFactor2 = LTDC_BLENDING_FACTOR2_PAxCA;
  pLayerCfg1.FBStartAdress = 0xC001FE00;
  pLayerCfg1.ImageWidth = 480;
  pLayerCfg1.ImageHeight = 140;
  pLayerCfg1.Backcolor.Blue = 0;
  pLayerCfg1.Backcolor.Green = 0;
  pLayerCfg1.Backcolor.Red = 0;
  if (HAL_LTDC_ConfigLayer(&hltdc, &pLayerCfg1, 1) != HAL_OK)
  {
    Error_Handler();
  }

}

static void MX_SAI2_Init(void)
{

  hsai_BlockA2.Instance = SAI2_Block_A;
  hsai_BlockA2.Init.Protocol = SAI_FREE_PROTOCOL;
  hsai_BlockA2.Init.AudioMode = SAI_MODEMASTER_TX;
  hsai_BlockA2.Init.DataSize = SAI_DATASIZE_8;
  hsai_BlockA2.Init.FirstBit = SAI_FIRSTBIT_MSB;
  hsai_BlockA2.Init.ClockStrobing = SAI_CLOCKSTROBING_FALLINGEDGE;
  hsai_BlockA2.Init.Synchro = SAI_ASYNCHRONOUS;
  hsai_BlockA2.Init.OutputDrive = SAI_OUTPUTDRIVE_DISABLE;
  hsai_BlockA2.Init.NoDivider = SAI_MASTERDIVIDER_ENABLE;
  hsai_BlockA2.Init.FIFOThreshold = SAI_FIFOTHRESHOLD_EMPTY;
  hsai_BlockA2.Init.AudioFrequency = SAI_AUDIO_FREQUENCY_48K;
  hsai_BlockA2.Init.SynchroExt = SAI_SYNCEXT_DISABLE;
  hsai_BlockA2.Init.MonoStereoMode = SAI_STEREOMODE;
  hsai_BlockA2.Init.CompandingMode = SAI_NOCOMPANDING;
  hsai_BlockA2.Init.TriState = SAI_OUTPUT_NOTRELEASED;
  hsai_BlockA2.FrameInit.FrameLength = 8;
  hsai_BlockA2.FrameInit.ActiveFrameLength = 1;
  hsai_BlockA2.FrameInit.FSDefinition = SAI_FS_STARTFRAME;
  hsai_BlockA2.FrameInit.FSPolarity = SAI_FS_ACTIVE_LOW;
  hsai_BlockA2.FrameInit.FSOffset = SAI_FS_FIRSTBIT;
  hsai_BlockA2.SlotInit.FirstBitOffset = 0;
  hsai_BlockA2.SlotInit.SlotSize = SAI_SLOTSIZE_DATASIZE;
  hsai_BlockA2.SlotInit.SlotNumber = 1;
  hsai_BlockA2.SlotInit.SlotActive = 0x00000000;
  if (HAL_SAI_Init(&hsai_BlockA2) != HAL_OK)
  {
    Error_Handler();
  }
  hsai_BlockB2.Instance = SAI2_Block_B;
  hsai_BlockB2.Init.Protocol = SAI_FREE_PROTOCOL;
  hsai_BlockB2.Init.AudioMode = SAI_MODESLAVE_RX;
  hsai_BlockB2.Init.DataSize = SAI_DATASIZE_8;
  hsai_BlockB2.Init.FirstBit = SAI_FIRSTBIT_MSB;
  hsai_BlockB2.Init.ClockStrobing = SAI_CLOCKSTROBING_FALLINGEDGE;
  hsai_BlockB2.Init.Synchro = SAI_SYNCHRONOUS;
  hsai_BlockB2.Init.OutputDrive = SAI_OUTPUTDRIVE_DISABLE;
  hsai_BlockB2.Init.FIFOThreshold = SAI_FIFOTHRESHOLD_EMPTY;
  hsai_BlockB2.Init.SynchroExt = SAI_SYNCEXT_DISABLE;
  hsai_BlockB2.Init.MonoStereoMode = SAI_STEREOMODE;
  hsai_BlockB2.Init.CompandingMode = SAI_NOCOMPANDING;
  hsai_BlockB2.Init.TriState = SAI_OUTPUT_NOTRELEASED;
  hsai_BlockB2.FrameInit.FrameLength = 8;
  hsai_BlockB2.FrameInit.ActiveFrameLength = 1;
  hsai_BlockB2.FrameInit.FSDefinition = SAI_FS_STARTFRAME;
  hsai_BlockB2.FrameInit.FSPolarity = SAI_FS_ACTIVE_LOW;
  hsai_BlockB2.FrameInit.FSOffset = SAI_FS_FIRSTBIT;
  hsai_BlockB2.SlotInit.FirstBitOffset = 0;
  hsai_BlockB2.SlotInit.SlotSize = SAI_SLOTSIZE_DATASIZE;
  hsai_BlockB2.SlotInit.SlotNumber = 1;
  hsai_BlockB2.SlotInit.SlotActive = 0x00000000;
  if (HAL_SAI_Init(&hsai_BlockB2) != HAL_OK)
  {
    Error_Handler();
  }

}

static void MX_SDMMC1_SD_Init(void)
{

  hsd1.Instance = SDMMC1;
  hsd1.Init.ClockEdge = SDMMC_CLOCK_EDGE_RISING;
  hsd1.Init.ClockBypass = SDMMC_CLOCK_BYPASS_DISABLE;
  hsd1.Init.ClockPowerSave = SDMMC_CLOCK_POWER_SAVE_DISABLE;
  hsd1.Init.BusWide = SDMMC_BUS_WIDE_1B;
  hsd1.Init.HardwareFlowControl = SDMMC_HARDWARE_FLOW_CONTROL_DISABLE;
  hsd1.Init.ClockDiv = 0;

}

static void MX_USART1_UART_Init(void)
{

  huart1.Instance = USART1;
  huart1.Init.BaudRate = 115200;
  huart1.Init.WordLength = UART_WORDLENGTH_8B;
  huart1.Init.StopBits = UART_STOPBITS_1;
  huart1.Init.Parity = UART_PARITY_NONE;
  huart1.Init.Mode = UART_MODE_TX_RX;
  huart1.Init.HwFlowCtl = UART_HWCONTROL_NONE;
  huart1.Init.OverSampling = UART_OVERSAMPLING_16;
  huart1.Init.OneBitSampling = UART_ONE_BIT_SAMPLE_DISABLE;
  huart1.AdvancedInit.AdvFeatureInit = UART_ADVFEATURE_NO_INIT;
  if (HAL_UART_Init(&huart1) != HAL_OK)
  {
    Error_Handler();
  }

}

static void MX_DMA_Init(void)
{

  /* DMA controller clock enable */
  __HAL_RCC_DMA2_CLK_ENABLE();

  /* DMA interrupt init */
  /* DMA2_Stream3_IRQn interrupt configuration */
  HAL_NVIC_SetPriority(DMA2_Stream3_IRQn, 5, 0);
  HAL_NVIC_EnableIRQ(DMA2_Stream3_IRQn);
  /* DMA2_Stream4_IRQn interrupt configuration */
  HAL_NVIC_SetPriority(DMA2_Stream4_IRQn, 5, 0);
  HAL_NVIC_EnableIRQ(DMA2_Stream4_IRQn);
  /* DMA2_Stream6_IRQn interrupt configuration */
  HAL_NVIC_SetPriority(DMA2_Stream6_IRQn, 5, 0);
  HAL_NVIC_EnableIRQ(DMA2_Stream6_IRQn);
  /* DMA2_Stream7_IRQn interrupt configuration */
  HAL_NVIC_SetPriority(DMA2_Stream7_IRQn, 5, 0);
  HAL_NVIC_EnableIRQ(DMA2_Stream7_IRQn);

}

/* FMC initialization function */
static void MX_FMC_Init(void)
{

  FMC_SDRAM_TimingTypeDef SdramTiming = {0};

  /** Perform the SDRAM1 memory initialization sequence
  */
  hsdram1.Instance = FMC_SDRAM_DEVICE;
  /* hsdram1.Init */
  hsdram1.Init.SDBank = FMC_SDRAM_BANK1;
  hsdram1.Init.ColumnBitsNumber = FMC_SDRAM_COLUMN_BITS_NUM_8;
  hsdram1.Init.RowBitsNumber = FMC_SDRAM_ROW_BITS_NUM_12;
  hsdram1.Init.MemoryDataWidth = FMC_SDRAM_MEM_BUS_WIDTH_16;
  hsdram1.Init.InternalBankNumber = FMC_SDRAM_INTERN_BANKS_NUM_4;
  hsdram1.Init.CASLatency = FMC_SDRAM_CAS_LATENCY_1;
  hsdram1.Init.WriteProtection = FMC_SDRAM_WRITE_PROTECTION_DISABLE;
  hsdram1.Init.SDClockPeriod = FMC_SDRAM_CLOCK_DISABLE;
  hsdram1.Init.ReadBurst = FMC_SDRAM_RBURST_DISABLE;
  hsdram1.Init.ReadPipeDelay = FMC_SDRAM_RPIPE_DELAY_0;
  /* SdramTiming */
  SdramTiming.LoadToActiveDelay = 16;
  SdramTiming.ExitSelfRefreshDelay = 16;
  SdramTiming.SelfRefreshTime = 16;
  SdramTiming.RowCycleDelay = 16;
  SdramTiming.WriteRecoveryTime = 16;
  SdramTiming.RPDelay = 16;
  SdramTiming.RCDDelay = 16;

  if (HAL_SDRAM_Init(&hsdram1, &SdramTiming) != HAL_OK)
  {
    Error_Handler( );
  }

}

static void MX_GPIO_Init(void)
{
  GPIO_InitTypeDef GPIO_InitStruct = {0};

  /* GPIO Ports Clock Enable */
  __HAL_RCC_GPIOE_CLK_ENABLE();
  __HAL_RCC_GPIOG_CLK_ENABLE();
  __HAL_RCC_GPIOB_CLK_ENABLE();
  __HAL_RCC_GPIOD_CLK_ENABLE();
  __HAL_RCC_GPIOC_CLK_ENABLE();
  __HAL_RCC_GPIOA_CLK_ENABLE();
  __HAL_RCC_GPIOJ_CLK_ENABLE();
  __HAL_RCC_GPIOI_CLK_ENABLE();
  __HAL_RCC_GPIOK_CLK_ENABLE();
  __HAL_RCC_GPIOF_CLK_ENABLE();
  __HAL_RCC_GPIOH_CLK_ENABLE();

  /*Configure GPIO pin Output Level */
  HAL_GPIO_WritePin(OTG_FS_PowerSwitchOn_GPIO_Port, OTG_FS_PowerSwitchOn_Pin, GPIO_PIN_SET);

  /*Configure GPIO pin Output Level */
  HAL_GPIO_WritePin(GPIOI, ARDUINO_D7_Pin|ARDUINO_D8_Pin|LCD_DISP_Pin, GPIO_PIN_RESET);

  /*Configure GPIO pin Output Level */
  HAL_GPIO_WritePin(LCD_BL_CTRL_GPIO_Port, LCD_BL_CTRL_Pin, GPIO_PIN_RESET);

  /*Configure GPIO pin Output Level */
  HAL_GPIO_WritePin(GPIOH, DCMI_PWR_EN_Pin|LED2_Pin, GPIO_PIN_RESET);

  /*Configure GPIO pin Output Level */
  HAL_GPIO_WritePin(GPIOG, ARDUINO_D4_Pin|ARDUINO_D2_Pin|EXT_RST_Pin, GPIO_PIN_RESET);

  /*Configure GPIO pin : OTG_HS_OverCurrent_Pin */
  GPIO_InitStruct.Pin = OTG_HS_OverCurrent_Pin;
  GPIO_InitStruct.Mode = GPIO_MODE_INPUT;
  GPIO_InitStruct.Pull = GPIO_NOPULL;
  HAL_GPIO_Init(OTG_HS_OverCurrent_GPIO_Port, &GPIO_InitStruct);

  /*Configure GPIO pin : QSPI_D2_Pin */
  GPIO_InitStruct.Pin = QSPI_D2_Pin;
  GPIO_InitStruct.Mode = GPIO_MODE_AF_PP;
  GPIO_InitStruct.Pull = GPIO_NOPULL;
  GPIO_InitStruct.Speed = GPIO_SPEED_FREQ_VERY_HIGH;
  GPIO_InitStruct.Alternate = GPIO_AF9_QUADSPI;
  HAL_GPIO_Init(QSPI_D2_GPIO_Port, &GPIO_InitStruct);

  /*Configure GPIO pins : RMII_TXD1_Pin RMII_TXD0_Pin RMII_TX_EN_Pin */
  GPIO_InitStruct.Pin = RMII_TXD1_Pin|RMII_TXD0_Pin|RMII_TX_EN_Pin;
  GPIO_InitStruct.Mode = GPIO_MODE_AF_PP;
  GPIO_InitStruct.Pull = GPIO_NOPULL;
  GPIO_InitStruct.Speed = GPIO_SPEED_FREQ_VERY_HIGH;
  GPIO_InitStruct.Alternate = GPIO_AF11_ETH;
  HAL_GPIO_Init(GPIOG, &GPIO_InitStruct);

  /*Configure GPIO pins : ULPI_D7_Pin ULPI_D6_Pin ULPI_D5_Pin ULPI_D3_Pin
                           ULPI_D2_Pin ULPI_D1_Pin ULPI_D4_Pin */
  GPIO_InitStruct.Pin = ULPI_D7_Pin|ULPI_D6_Pin|ULPI_D5_Pin|ULPI_D3_Pin
                          |ULPI_D2_Pin|ULPI_D1_Pin|ULPI_D4_Pin;
  GPIO_InitStruct.Mode = GPIO_MODE_AF_PP;
  GPIO_InitStruct.Pull = GPIO_NOPULL;
  GPIO_InitStruct.Speed = GPIO_SPEED_FREQ_VERY_HIGH;
  GPIO_InitStruct.Alternate = GPIO_AF10_OTG_HS;
  HAL_GPIO_Init(GPIOB, &GPIO_InitStruct);

  /*Configure GPIO pin : ARDUINO_PWM_D3_Pin */
  GPIO_InitStruct.Pin = ARDUINO_PWM_D3_Pin;
  GPIO_InitStruct.Mode = GPIO_MODE_AF_PP;
  GPIO_InitStruct.Pull = GPIO_NOPULL;
  GPIO_InitStruct.Speed = GPIO_SPEED_FREQ_LOW;
  GPIO_InitStruct.Alternate = GPIO_AF2_TIM3;
  HAL_GPIO_Init(ARDUINO_PWM_D3_GPIO_Port, &GPIO_InitStruct);

  /*Configure GPIO pin : SPDIF_RX0_Pin */
  GPIO_InitStruct.Pin = SPDIF_RX0_Pin;
  GPIO_InitStruct.Mode = GPIO_MODE_AF_PP;
  GPIO_InitStruct.Pull = GPIO_NOPULL;
  GPIO_InitStruct.Speed = GPIO_SPEED_FREQ_LOW;
  GPIO_InitStruct.Alternate = GPIO_AF8_SPDIFRX;
  HAL_GPIO_Init(SPDIF_RX0_GPIO_Port, &GPIO_InitStruct);

  /*Configure GPIO pin : ARDUINO_PWM_D9_Pin */
  GPIO_InitStruct.Pin = ARDUINO_PWM_D9_Pin;
  GPIO_InitStruct.Mode = GPIO_MODE_AF_PP;
  GPIO_InitStruct.Pull = GPIO_NOPULL;
  GPIO_InitStruct.Speed = GPIO_SPEED_FREQ_LOW;
  GPIO_InitStruct.Alternate = GPIO_AF1_TIM2;
  HAL_GPIO_Init(ARDUINO_PWM_D9_GPIO_Port, &GPIO_InitStruct);

  /*Configure GPIO pins : DCMI_D6_Pin DCMI_D7_Pin */
  GPIO_InitStruct.Pin = DCMI_D6_Pin|DCMI_D7_Pin;
  GPIO_InitStruct.Mode = GPIO_MODE_AF_PP;
  GPIO_InitStruct.Pull = GPIO_NOPULL;
  GPIO_InitStruct.Speed = GPIO_SPEED_FREQ_LOW;
  GPIO_InitStruct.Alternate = GPIO_AF13_DCMI;
  HAL_GPIO_Init(GPIOE, &GPIO_InitStruct);

  /*Configure GPIO pin : QSPI_NCS_Pin */
  GPIO_InitStruct.Pin = QSPI_NCS_Pin;
  GPIO_InitStruct.Mode = GPIO_MODE_AF_PP;
  GPIO_InitStruct.Pull = GPIO_NOPULL;
  GPIO_InitStruct.Speed = GPIO_SPEED_FREQ_VERY_HIGH;
  GPIO_InitStruct.Alternate = GPIO_AF10_QUADSPI;
  HAL_GPIO_Init(QSPI_NCS_GPIO_Port, &GPIO_InitStruct);

  /*Configure GPIO pin : OTG_FS_VBUS_Pin */
  GPIO_InitStruct.Pin = OTG_FS_VBUS_Pin;
  GPIO_InitStruct.Mode = GPIO_MODE_INPUT;
  GPIO_InitStruct.Pull = GPIO_NOPULL;
  HAL_GPIO_Init(OTG_FS_VBUS_GPIO_Port, &GPIO_InitStruct);

  /*Configure GPIO pin : Audio_INT_Pin */
  GPIO_InitStruct.Pin = Audio_INT_Pin;
  GPIO_InitStruct.Mode = GPIO_MODE_EVT_RISING;
  GPIO_InitStruct.Pull = GPIO_NOPULL;
  HAL_GPIO_Init(Audio_INT_GPIO_Port, &GPIO_InitStruct);

  /*Configure GPIO pins : OTG_FS_P_Pin OTG_FS_N_Pin OTG_FS_ID_Pin */
  GPIO_InitStruct.Pin = OTG_FS_P_Pin|OTG_FS_N_Pin|OTG_FS_ID_Pin;
  GPIO_InitStruct.Mode = GPIO_MODE_AF_PP;
  GPIO_InitStruct.Pull = GPIO_NOPULL;
  GPIO_InitStruct.Speed = GPIO_SPEED_FREQ_VERY_HIGH;
  GPIO_InitStruct.Alternate = GPIO_AF10_OTG_FS;
  HAL_GPIO_Init(GPIOA, &GPIO_InitStruct);

  /*Configure GPIO pin : OTG_FS_PowerSwitchOn_Pin */
  GPIO_InitStruct.Pin = OTG_FS_PowerSwitchOn_Pin;
  GPIO_InitStruct.Mode = GPIO_MODE_OUTPUT_PP;
  GPIO_InitStruct.Pull = GPIO_NOPULL;
  GPIO_InitStruct.Speed = GPIO_SPEED_FREQ_LOW;
  HAL_GPIO_Init(OTG_FS_PowerSwitchOn_GPIO_Port, &GPIO_InitStruct);

  /*Configure GPIO pin : DCMI_D5_Pin */
  GPIO_InitStruct.Pin = DCMI_D5_Pin;
  GPIO_InitStruct.Mode = GPIO_MODE_AF_PP;
  GPIO_InitStruct.Pull = GPIO_NOPULL;
  GPIO_InitStruct.Speed = GPIO_SPEED_FREQ_LOW;
  GPIO_InitStruct.Alternate = GPIO_AF13_DCMI;
  HAL_GPIO_Init(DCMI_D5_GPIO_Port, &GPIO_InitStruct);

  /*Configure GPIO pins : ARDUINO_D7_Pin ARDUINO_D8_Pin LCD_DISP_Pin */
  GPIO_InitStruct.Pin = ARDUINO_D7_Pin|ARDUINO_D8_Pin|LCD_DISP_Pin;
  GPIO_InitStruct.Mode = GPIO_MODE_OUTPUT_PP;
  GPIO_InitStruct.Pull = GPIO_NOPULL;
  GPIO_InitStruct.Speed = GPIO_SPEED_FREQ_LOW;
  HAL_GPIO_Init(GPIOI, &GPIO_InitStruct);

  /*Configure GPIO pin : uSD_Detect_Pin */
  GPIO_InitStruct.Pin = uSD_Detect_Pin;
  GPIO_InitStruct.Mode = GPIO_MODE_INPUT;
  GPIO_InitStruct.Pull = GPIO_NOPULL;
  HAL_GPIO_Init(uSD_Detect_GPIO_Port, &GPIO_InitStruct);

  /*Configure GPIO pin : LCD_BL_CTRL_Pin */
  GPIO_InitStruct.Pin = LCD_BL_CTRL_Pin;
  GPIO_InitStruct.Mode = GPIO_MODE_OUTPUT_PP;
  GPIO_InitStruct.Pull = GPIO_NOPULL;
  GPIO_InitStruct.Speed = GPIO_SPEED_FREQ_LOW;
  HAL_GPIO_Init(LCD_BL_CTRL_GPIO_Port, &GPIO_InitStruct);

  /*Configure GPIO pin : DCMI_VSYNC_Pin */
  GPIO_InitStruct.Pin = DCMI_VSYNC_Pin;
  GPIO_InitStruct.Mode = GPIO_MODE_AF_PP;
  GPIO_InitStruct.Pull = GPIO_NOPULL;
  GPIO_InitStruct.Speed = GPIO_SPEED_FREQ_LOW;
  GPIO_InitStruct.Alternate = GPIO_AF13_DCMI;
  HAL_GPIO_Init(DCMI_VSYNC_GPIO_Port, &GPIO_InitStruct);

  /*Configure GPIO pin : OTG_FS_OverCurrent_Pin */
  GPIO_InitStruct.Pin = OTG_FS_OverCurrent_Pin;
  GPIO_InitStruct.Mode = GPIO_MODE_INPUT;
  GPIO_InitStruct.Pull = GPIO_NOPULL;
  HAL_GPIO_Init(OTG_FS_OverCurrent_GPIO_Port, &GPIO_InitStruct);

  /*Configure GPIO pins : TP3_Pin NC2_Pin */
  GPIO_InitStruct.Pin = TP3_Pin|NC2_Pin;
  GPIO_InitStruct.Mode = GPIO_MODE_INPUT;
  GPIO_InitStruct.Pull = GPIO_NOPULL;
  HAL_GPIO_Init(GPIOH, &GPIO_InitStruct);

  /*Configure GPIO pin : ARDUINO_SCK_D13_Pin */
  GPIO_InitStruct.Pin = ARDUINO_SCK_D13_Pin;
  GPIO_InitStruct.Mode = GPIO_MODE_AF_PP;
  GPIO_InitStruct.Pull = GPIO_NOPULL;
  GPIO_InitStruct.Speed = GPIO_SPEED_FREQ_LOW;
  GPIO_InitStruct.Alternate = GPIO_AF5_SPI2;
  HAL_GPIO_Init(ARDUINO_SCK_D13_GPIO_Port, &GPIO_InitStruct);

  /*Configure GPIO pins : DCMI_PWR_EN_Pin LED2_Pin */
  GPIO_InitStruct.Pin = DCMI_PWR_EN_Pin|LED2_Pin;
  GPIO_InitStruct.Mode = GPIO_MODE_OUTPUT_PP;
  GPIO_InitStruct.Pull = GPIO_NOPULL;
  GPIO_InitStruct.Speed = GPIO_SPEED_FREQ_LOW;
  HAL_GPIO_Init(GPIOH, &GPIO_InitStruct);

  /*Configure GPIO pins : DCMI_D4_Pin DCMI_D3_Pin DCMI_D0_Pin DCMI_D2_Pin
                           DCMI_D1_Pin */
  GPIO_InitStruct.Pin = DCMI_D4_Pin|DCMI_D3_Pin|DCMI_D0_Pin|DCMI_D2_Pin
                          |DCMI_D1_Pin;
  GPIO_InitStruct.Mode = GPIO_MODE_AF_PP;
  GPIO_InitStruct.Pull = GPIO_NOPULL;
  GPIO_InitStruct.Speed = GPIO_SPEED_FREQ_LOW;
  GPIO_InitStruct.Alternate = GPIO_AF13_DCMI;
  HAL_GPIO_Init(GPIOH, &GPIO_InitStruct);

  /*Configure GPIO pin : ARDUINO_PWM_CS_D5_Pin */
  GPIO_InitStruct.Pin = ARDUINO_PWM_CS_D5_Pin;
  GPIO_InitStruct.Mode = GPIO_MODE_AF_PP;
  GPIO_InitStruct.Pull = GPIO_NOPULL;
  GPIO_InitStruct.Speed = GPIO_SPEED_FREQ_LOW;
  GPIO_InitStruct.Alternate = GPIO_AF2_TIM5;
  HAL_GPIO_Init(ARDUINO_PWM_CS_D5_GPIO_Port, &GPIO_InitStruct);

  /*Configure GPIO pin : ARDUINO_PWM_D10_Pin */
  GPIO_InitStruct.Pin = ARDUINO_PWM_D10_Pin;
  GPIO_InitStruct.Mode = GPIO_MODE_AF_PP;
  GPIO_InitStruct.Pull = GPIO_NOPULL;
  GPIO_InitStruct.Speed = GPIO_SPEED_FREQ_LOW;
  GPIO_InitStruct.Alternate = GPIO_AF1_TIM1;
  HAL_GPIO_Init(ARDUINO_PWM_D10_GPIO_Port, &GPIO_InitStruct);

  /*Configure GPIO pin : LCD_INT_Pin */
  GPIO_InitStruct.Pin = LCD_INT_Pin;
  GPIO_InitStruct.Mode = GPIO_MODE_EVT_RISING;
  GPIO_InitStruct.Pull = GPIO_NOPULL;
  HAL_GPIO_Init(LCD_INT_GPIO_Port, &GPIO_InitStruct);

  /*Configure GPIO pins : ARDUINO_RX_D0_Pin ARDUINO_TX_D1_Pin */
  GPIO_InitStruct.Pin = ARDUINO_RX_D0_Pin|ARDUINO_TX_D1_Pin;
  GPIO_InitStruct.Mode = GPIO_MODE_AF_PP;
  GPIO_InitStruct.Pull = GPIO_NOPULL;
  GPIO_InitStruct.Speed = GPIO_SPEED_FREQ_VERY_HIGH;
  GPIO_InitStruct.Alternate = GPIO_AF8_USART6;
  HAL_GPIO_Init(GPIOC, &GPIO_InitStruct);

  /*Configure GPIO pin : ULPI_NXT_Pin */
  GPIO_InitStruct.Pin = ULPI_NXT_Pin;
  GPIO_InitStruct.Mode = GPIO_MODE_AF_PP;
  GPIO_InitStruct.Pull = GPIO_NOPULL;
  GPIO_InitStruct.Speed = GPIO_SPEED_FREQ_VERY_HIGH;
  GPIO_InitStruct.Alternate = GPIO_AF10_OTG_HS;
  HAL_GPIO_Init(ULPI_NXT_GPIO_Port, &GPIO_InitStruct);

  /*Configure GPIO pins : ARDUINO_D4_Pin ARDUINO_D2_Pin EXT_RST_Pin */
  GPIO_InitStruct.Pin = ARDUINO_D4_Pin|ARDUINO_D2_Pin|EXT_RST_Pin;
  GPIO_InitStruct.Mode = GPIO_MODE_OUTPUT_PP;
  GPIO_InitStruct.Pull = GPIO_NOPULL;
  GPIO_InitStruct.Speed = GPIO_SPEED_FREQ_LOW;
  HAL_GPIO_Init(GPIOG, &GPIO_InitStruct);

  /*Configure GPIO pins : ARDUINO_A4_Pin ARDUINO_A5_Pin ARDUINO_A1_Pin ARDUINO_A2_Pin
                           ARDUINO_A3_Pin */
  GPIO_InitStruct.Pin = ARDUINO_A4_Pin|ARDUINO_A5_Pin|ARDUINO_A1_Pin|ARDUINO_A2_Pin
                          |ARDUINO_A3_Pin;
  GPIO_InitStruct.Mode = GPIO_MODE_ANALOG;
  GPIO_InitStruct.Pull = GPIO_NOPULL;
  HAL_GPIO_Init(GPIOF, &GPIO_InitStruct);

  /*Configure GPIO pins : ULPI_STP_Pin ULPI_DIR_Pin */
  GPIO_InitStruct.Pin = ULPI_STP_Pin|ULPI_DIR_Pin;
  GPIO_InitStruct.Mode = GPIO_MODE_AF_PP;
  GPIO_InitStruct.Pull = GPIO_NOPULL;
  GPIO_InitStruct.Speed = GPIO_SPEED_FREQ_VERY_HIGH;
  GPIO_InitStruct.Alternate = GPIO_AF10_OTG_HS;
  HAL_GPIO_Init(GPIOC, &GPIO_InitStruct);

  /*Configure GPIO pins : RMII_MDC_Pin RMII_RXD0_Pin RMII_RXD1_Pin */
  GPIO_InitStruct.Pin = RMII_MDC_Pin|RMII_RXD0_Pin|RMII_RXD1_Pin;
  GPIO_InitStruct.Mode = GPIO_MODE_AF_PP;
  GPIO_InitStruct.Pull = GPIO_NOPULL;
  GPIO_InitStruct.Speed = GPIO_SPEED_FREQ_VERY_HIGH;
  GPIO_InitStruct.Alternate = GPIO_AF11_ETH;
  HAL_GPIO_Init(GPIOC, &GPIO_InitStruct);

  /*Configure GPIO pins : QSPI_D1_Pin QSPI_D3_Pin QSPI_D0_Pin */
  GPIO_InitStruct.Pin = QSPI_D1_Pin|QSPI_D3_Pin|QSPI_D0_Pin;
  GPIO_InitStruct.Mode = GPIO_MODE_AF_PP;
  GPIO_InitStruct.Pull = GPIO_NOPULL;
  GPIO_InitStruct.Speed = GPIO_SPEED_FREQ_VERY_HIGH;
  GPIO_InitStruct.Alternate = GPIO_AF9_QUADSPI;
  HAL_GPIO_Init(GPIOD, &GPIO_InitStruct);

  /*Configure GPIO pin : RMII_RXER_Pin */
  GPIO_InitStruct.Pin = RMII_RXER_Pin;
  GPIO_InitStruct.Mode = GPIO_MODE_INPUT;
  GPIO_InitStruct.Pull = GPIO_NOPULL;
  HAL_GPIO_Init(RMII_RXER_GPIO_Port, &GPIO_InitStruct);

  /*Configure GPIO pins : RMII_REF_CLK_Pin RMII_MDIO_Pin RMII_CRS_DV_Pin */
  GPIO_InitStruct.Pin = RMII_REF_CLK_Pin|RMII_MDIO_Pin|RMII_CRS_DV_Pin;
  GPIO_InitStruct.Mode = GPIO_MODE_AF_PP;
  GPIO_InitStruct.Pull = GPIO_NOPULL;
  GPIO_InitStruct.Speed = GPIO_SPEED_FREQ_VERY_HIGH;
  GPIO_InitStruct.Alternate = GPIO_AF11_ETH;
  HAL_GPIO_Init(GPIOA, &GPIO_InitStruct);

  /*Configure GPIO pin : ARDUINO_A0_Pin */
  GPIO_InitStruct.Pin = ARDUINO_A0_Pin;
  GPIO_InitStruct.Mode = GPIO_MODE_ANALOG;
  GPIO_InitStruct.Pull = GPIO_NOPULL;
  HAL_GPIO_Init(ARDUINO_A0_GPIO_Port, &GPIO_InitStruct);

  /*Configure GPIO pins : DCMI_HSYNC_Pin PA6 */
  GPIO_InitStruct.Pin = DCMI_HSYNC_Pin|GPIO_PIN_6;
  GPIO_InitStruct.Mode = GPIO_MODE_AF_PP;
  GPIO_InitStruct.Pull = GPIO_NOPULL;
  GPIO_InitStruct.Speed = GPIO_SPEED_FREQ_LOW;
  GPIO_InitStruct.Alternate = GPIO_AF13_DCMI;
  HAL_GPIO_Init(GPIOA, &GPIO_InitStruct);

  /*Configure GPIO pins : ULPI_CLK_Pin ULPI_D0_Pin */
  GPIO_InitStruct.Pin = ULPI_CLK_Pin|ULPI_D0_Pin;
  GPIO_InitStruct.Mode = GPIO_MODE_AF_PP;
  GPIO_InitStruct.Pull = GPIO_NOPULL;
  GPIO_InitStruct.Speed = GPIO_SPEED_FREQ_VERY_HIGH;
  GPIO_InitStruct.Alternate = GPIO_AF10_OTG_HS;
  HAL_GPIO_Init(GPIOA, &GPIO_InitStruct);

  /*Configure GPIO pins : ARDUINO_MISO_D12_Pin ARDUINO_MOSI_PWM_D11_Pin */
  GPIO_InitStruct.Pin = ARDUINO_MISO_D12_Pin|ARDUINO_MOSI_PWM_D11_Pin;
  GPIO_InitStruct.Mode = GPIO_MODE_AF_PP;
  GPIO_InitStruct.Pull = GPIO_NOPULL;
  GPIO_InitStruct.Speed = GPIO_SPEED_FREQ_LOW;
  GPIO_InitStruct.Alternate = GPIO_AF5_SPI2;
  HAL_GPIO_Init(GPIOB, &GPIO_InitStruct);

}

/* USER CODE BEGIN 4 */
void BSP_AUDIO_IN_TransferComplete_CallBack(void)
{
	audio_rec_buffer_state = BUFFER_OFFSET_FULL;
	return;
}

void BSP_AUDIO_IN_HalfTransfer_CallBack(void)
{
	audio_rec_buffer_state = BUFFER_OFFSET_HALF;
	return;
}

void write_header(uint32_t N_Bytes_Data){
	uint32_t byteswritten;
	uint8_t entete[] = { 0x52, 0x49, 0x46,
			0x46, //'RIFF' : identification du format
			(uint8_t) ((N_Bytes_Data+36) & MASK_32_TO_8_0),
			(uint8_t) (((N_Bytes_Data+36) & MASK_32_TO_8_1)>>8),
			(uint8_t) (((N_Bytes_Data+36) & MASK_32_TO_8_2)>>16),
			(uint8_t) (((N_Bytes_Data+36) & MASK_32_TO_8_3)>>24), //Taille du fichier - 8 octets (en octets)

			0x57, 0x41, 0x56,
			0x45, //'WAVE'
			0x66, 0x6D, 0x74,
			0x20, //'fmt ' identifiant le format WAV
			0x10, 0x00, 0x00,
			0x00, //Nombre d'octets utilisés pour définir le format (16)
			0x01,
			0x00, //Pas de compression, format PCM entier
			Audio_chan,
			0x00, //Nombre de cannaux
			(uint8_t) (Audio_freq & MASK_32_TO_8_0),
			(uint8_t) ((Audio_freq & MASK_32_TO_8_1)>>8),
			(uint8_t) ((Audio_freq & MASK_32_TO_8_2)>>16),
			(uint8_t) ((Audio_freq & MASK_32_TO_8_3)>>24), //Fréquence d'échantillonnage

			(uint8_t) (BytePerSec & MASK_32_TO_8_0),
			(uint8_t) ((BytePerSec & MASK_32_TO_8_1)>>8),
			(uint8_t) ((BytePerSec & MASK_32_TO_8_2)>>16),
			(uint8_t) ((BytePerSec & MASK_32_TO_8_3)>>24), //Nombre d'octets par seconde

			(BytePerBloc & MASK_32_TO_8_0), ((BytePerBloc & MASK_32_TO_8_1)<<8), //BytePerBloc

			(Audio_bit_res), 0x00, //Bits par échantillons (ici 16 par défaut)
			0x64, 0x61, 0x74, 0x61, //'DATA'
			//(DataSize & MASK_32_TO_8_0), (DataSize & MASK_32_TO_8_1), (DataSize& MASK_32_TO_8_2), (DataSize & MASK_32_TO_8_3)
			(uint8_t) ((N_Bytes_Data) & MASK_32_TO_8_0),
			(uint8_t) (((N_Bytes_Data) & MASK_32_TO_8_1)>>8),
			(uint8_t) (((N_Bytes_Data) & MASK_32_TO_8_2)>>16),
			(uint8_t) (((N_Bytes_Data) & MASK_32_TO_8_3)>>24),//DataSize
	};
	f_write(&SDFile, entete, 44, (void*) &byteswritten);
}

void Draw_Keyboard(uint8_t MAJ_ENABLE){
	uint16_t y = 132;

	BSP_LCD_SetFont(&Font16);
	BSP_LCD_SetBackColor(LCD_COLOR_BLACK);
	BSP_LCD_SetTextColor(LCD_COLOR_BLACK);
	BSP_LCD_FillRect(0, 132, 480, 140);

	BSP_LCD_SetTextColor(LCD_COLOR_GRAY);
	for(uint8_t i=0; i<5; i++){
		for(uint8_t j=0; j<10; j++){
			if(i<3)BSP_LCD_FillRect(j*48+2, y+i*28+2, 44, 24);
			else if(i==3){
				if(j == 0){
					if(MAJ_ENABLE)BSP_LCD_SetTextColor(LCD_COLOR_LIGHTGRAY);
					BSP_LCD_FillRect(j*48+2, y+i*28+2, 80, 24);
					if(MAJ_ENABLE)BSP_LCD_SetTextColor(LCD_COLOR_GRAY);
				}
				if(j == 8){
					BSP_LCD_FillRect(j*48+34, y+i*28+2, 60, 24);
				}
				else if(j >= 2 && j <= 7)BSP_LCD_FillRect(j*48+2, y+i*28+2, 44, 24);
			} else {
				if(j == 8){
					BSP_LCD_FillRect(j*48+14, y+i*28+2, 80, 24);
				}
				if(j == 2)BSP_LCD_FillRect(j*48+2+30, y+i*28+2, 44+48*5-60, 24);
			}
		}
	}

	BSP_LCD_SetBackColor(LCD_COLOR_GRAY);
	BSP_LCD_SetTextColor(LCD_COLOR_WHITE);
	for(uint8_t i=0; i<5; i++){
		for(uint8_t j=0; j<10; j++){
			if(keyboard[i][j] >= '0' && keyboard[i][j] <= '9')BSP_LCD_DisplayChar(j*48+2+16, y+i*28+2+4, keyboard[i][j]);
			if(keyboard[i][j] >= 'a' && keyboard[i][j] <= 'z')BSP_LCD_DisplayChar(j*48+2+16, y+i*28+2+4, keyboard[i][j]+('A'-'a')*MAJ_ENABLE);
			if(i == 3 && j == 8){
				BSP_LCD_DisplayStringAt(j*48+34+15, y+i*28+6, (uint8_t *)"DEL", LEFT_MODE);
			}
			if(i == 4 && j == 8){
				BSP_LCD_DisplayStringAt(j*48+44, y+i*28+6, (uint8_t *)"OK", LEFT_MODE);
			}
			if(i == 3 && j == 0){
				if(MAJ_ENABLE)BSP_LCD_SetBackColor(LCD_COLOR_LIGHTGRAY);
				BSP_LCD_DisplayStringAt(j*48+2+26, y+i*28+6, (uint8_t *)"MAJ", LEFT_MODE);
				if(MAJ_ENABLE)BSP_LCD_SetBackColor(LCD_COLOR_GRAY);
			}
			if(i == 4 && j == 2){
				BSP_LCD_DisplayStringAt(230, y+i*28+2, (uint8_t *)"__", LEFT_MODE);
			}
		}
	}
}
/* USER CODE BEGIN Header_KeyboardTask */
/**
* @brief Function implementing the KB thread.
* @param argument: Not used
* @retval None
*/
/* USER CODE END Header_KeyboardTask */
void KeyboardTask(void const * argument)
{
	/* USER CODE BEGIN KeyboardTask */
	uint8_t state = 0, idx=strlen((char *)Name), maj_en = 0;
	uint16_t Pressed_X, Pressed_Y;
	uint16_t x = 20;
	uint16_t y = 20;
	uint16_t Width = MAX_c*7;
	uint16_t Height = 12;

	TS_StateTypeDef  prev_state;
	TS_StateTypeDef TS_State;
	prev_state.touchDetected = 0;

	vTaskSuspend(inputHandle);

	BSP_LCD_SetLayerVisible(1, ENABLE);
	BSP_LCD_SelectLayer(1);
	BSP_LCD_Clear(0);

	xSemaphoreTake(mutex_LCDHandle, portMAX_DELAY);
	Draw_Keyboard(maj_en);
	xSemaphoreGive(mutex_LCDHandle);

	/* Infinite loop */
	for(;;)
	{
		xSemaphoreTake(mutex_LCDHandle, portMAX_DELAY);
		BSP_LCD_SetFont(&Font12);
		BSP_LCD_SetTextColor(LCD_COLOR_BLACK);
		BSP_LCD_SetBackColor(LCD_COLOR_WHITE);
		BSP_LCD_DisplayStringAt(69, y, Name, LEFT_MODE);
		xSemaphoreGive(mutex_LCDHandle);

		BSP_TS_GetState(&TS_State);
		if(TS_State.touchDetected != prev_state.touchDetected && TS_State.touchDetected < 2 && idx < MAX_c){
			prev_state.touchDetected = TS_State.touchDetected;
			switch (state){
			case 0:
				Pressed_X = TS_State.touchX[0]/48;
				Pressed_Y = (TS_State.touchY[0]-132)/28;
				state = 1;
				break;

			case 1:
				if(TS_State.touchX[0]/48 == Pressed_X && (TS_State.touchY[0]-132)/28 == Pressed_Y){
					state = 0;
					HAL_GPIO_TogglePin(LED2_GPIO_Port, LED2_Pin);
					if(keyboard[Pressed_Y][Pressed_X] == BACKSPACE){
						if(idx>0){
							Name[idx-1] = 0;
							BSP_LCD_SetTextColor(0xFFEEEEEE);
							BSP_LCD_FillRect(69+7*(idx-1), 20, 7, 12);
							idx--;
						}

					} else if(keyboard[Pressed_Y][Pressed_X] == ENTER){
						xSemaphoreTake(mutex_LCDHandle, portMAX_DELAY);
						BSP_LCD_SetTextColor(0xFFEEEEEE);
						BSP_LCD_FillRect(x+idx*7, y, x+Width-7*7, Height);
						BSP_LCD_SetTextColor(LCD_COLOR_BLUE);
						xSemaphoreGive(mutex_LCDHandle);
						BSP_LCD_SetLayerVisible(1, DISABLE);
						BSP_LCD_SelectLayer(0);
						if(strncmp((char *)Name,"circle_",7) == 0){
							BSP_LCD_DrawCircle((Name[7]-'0')*100+(Name[8]-'0')*10+(Name[9]-'0'), (Name[11]-'0')*100+(Name[12]-'0')*10+(Name[13]-'0'), (Name[15]-'0')*10+Name[16]-'0');
						} else {
						/* definition and creation of SD */
							osThreadDef(SD, SDTask, osPriorityHigh, 0, 6096);
							SDHandle = osThreadCreate(osThread(SD), NULL);
						}
						vTaskResume(inputHandle);
						vTaskDelete(KBHandle);

					}else if(keyboard[Pressed_Y][Pressed_X] == MAJ){
						maj_en = !maj_en;
						Draw_Keyboard(maj_en);
					}else{
						if(keyboard[Pressed_Y][Pressed_X] >= 'A' && keyboard[Pressed_Y][Pressed_X] <= 'z')Name[idx++] = keyboard[Pressed_Y][Pressed_X]+('A'-'a')*maj_en;
						else Name[idx++] = keyboard[Pressed_Y][Pressed_X];
					}

				} else if(TS_State.touchY[0] < 132){
					xSemaphoreTake(mutex_LCDHandle, portMAX_DELAY);
					BSP_LCD_SetTextColor(0xFFEEEEEE);
					BSP_LCD_FillRect(x+idx*7, y, x+Width-7*7, Height);
					BSP_LCD_SetTextColor(LCD_COLOR_BLUE);
					xSemaphoreGive(mutex_LCDHandle);
					BSP_LCD_SetLayerVisible(1, DISABLE);
					BSP_LCD_SelectLayer(0);
					vTaskResume(inputHandle);
					vTaskDelete(KBHandle);
				}else state = 0;

				break;

			default:
				state = 0;
				break;
			}
		}
		osDelay(10);
	}
	/* USER CODE END KeyboardTask */
}

/* USER CODE END 4 */

void StartDefaultTask(void const * argument)
{
	for(;;)
	{
		osDelay(1);
	}
}

void SDTask(void const * argument)
{
  /* USER CODE BEGIN SDTask */
	FRESULT res; /* FatFs function common result code */
	uint32_t byteswritten; /* File write/read counts */
	uint8_t wtext[] = "La version v1.16.1 ne devrait plus poser de soucis :)"; /* File write buffer */
	uint8_t file_name[34];
	sprintf((char *) file_name, "%s.TXT",Name);
	BSP_LCD_DisplayStringAt(20, 80, file_name, LEFT_MODE);
	uint8_t rtext[_MAX_SS];/* File read buffer */
	if(f_mount(&SDFatFS, (TCHAR const*)SDPath, 0) != FR_OK)
	{
		Error_Handler();
	}
	else
	{
		if(f_mkfs((TCHAR const*)SDPath, FM_ANY, 0, rtext, sizeof(rtext)) != FR_OK)
		{
			Error_Handler();
		}
		else
		{
			//Open file for writing (Create)
			if(f_open(&SDFile,"EEA.TXT", FA_CREATE_ALWAYS | FA_WRITE) != FR_OK)
			{

				Error_Handler();
			}
			else
			{
				//Write to the text file
				res = f_write(&SDFile, wtext, strlen((char *)wtext), (void *)&byteswritten);
				if((byteswritten == 0) || (res != FR_OK))
				{
					Error_Handler();
				}
				else
				{
					f_close(&SDFile);
				}
			}
		}
	}
	BSP_LCD_DisplayStringAt(100, 80, "OK", LEFT_MODE);
	//f_mount(&SDFatFS, (TCHAR const*)NULL, 0);
	vTaskDelete(SDHandle);
	/* Infinite loop */
	for(;;)
	{
		osDelay(1000);
	}
  /* USER CODE END SDTask */
}

void AudioTask(void const * argument)
{
  /* USER CODE BEGIN AudioTask */
	if (BSP_AUDIO_IN_OUT_Init(INPUT_DEVICE_DIGITAL_MICROPHONE_2, OUTPUT_DEVICE_HEADPHONE, 16000, DEFAULT_AUDIO_IN_BIT_RESOLUTION, DEFAULT_AUDIO_IN_CHANNEL_NBR) == AUDIO_OK)
	{
		BSP_LCD_SetBackColor(LCD_COLOR_WHITE);
		BSP_LCD_SetTextColor(LCD_COLOR_GREEN);
		BSP_LCD_DisplayStringAt(0, BSP_LCD_GetYSize() - 90, (uint8_t *)"  AUDIO RECORD INIT OK  ", CENTER_MODE);
	}

	/* Initialize SDRAM buffers */
//	memset((uint16_t*)AUDIO_BUFFER_IN, 0, AUDIO_BLOCK_SIZE*2);
//	memset((uint16_t*)AUDIO_BUFFER_OUT, 0, AUDIO_BLOCK_SIZE*2);
//	audio_rec_buffer_state = BUFFER_OFFSET_NONE;
//
//	/* Start Recording */
//	BSP_AUDIO_IN_Record((uint16_t*)AUDIO_BUFFER_IN, AUDIO_BLOCK_SIZE);
//	BSP_AUDIO_IN_SetVolume(90);
//	/* Start Playback */
//	BSP_AUDIO_OUT_SetAudioFrameSlot(CODEC_AUDIOFRAME_SLOT_02);
//	BSP_AUDIO_OUT_Play((uint16_t*)AUDIO_BUFFER_OUT, AUDIO_BLOCK_SIZE*2);
	/* Infinite loop */
	for(;;)
	{
//		while(audio_rec_buffer_state != BUFFER_OFFSET_HALF);
//		RL_sep((uint16_t*)AUDIO_BUFFER_IN,AUDIO_BLOCK_SIZE);
//		treatment();
//		RL_cat2((uint16_t*)AUDIO_BUFFER_OUT,AUDIO_BLOCK_SIZE);
//		while(audio_rec_buffer_state != BUFFER_OFFSET_FULL);
//		RL_sep((uint16_t*)(AUDIO_BUFFER_IN+(AUDIO_BLOCK_SIZE)),AUDIO_BLOCK_SIZE);
//		treatment();
//		RL_cat2((uint16_t*)(AUDIO_BUFFER_OUT+(AUDIO_BLOCK_SIZE)),AUDIO_BLOCK_SIZE);
		osDelay(100);
	}
  /* USER CODE END AudioTask */
}

void InputTask(void const * argument)
{
  /* USER CODE BEGIN InputTask */
	uint16_t x = 20;
	uint16_t y = 20;
	uint16_t Width = MAX_c*7;
	uint16_t Height = 12;
	uint8_t text[7] = "Name : ";
	uint16_t len = 7*strlen((char *)text);

	TS_StateTypeDef  prev_state;
	TS_StateTypeDef TS_State;

	uint8_t state = 0;

	BSP_LCD_SetTextColor(0xFFEEEEEE);
	BSP_LCD_FillRect(x+len, y, x+Width-len, Height);
	BSP_LCD_SetTextColor(LCD_COLOR_BLUE);

	BSP_LCD_DisplayStringAt(x, y, text, LEFT_MODE);

	/* Infinite loop */
	for(;;)
	{
		xSemaphoreTake(mutex_LCDHandle, portMAX_DELAY);
		BSP_LCD_SetFont(&Font12);
		BSP_LCD_SetTextColor(LCD_COLOR_BLACK);
		BSP_LCD_SetBackColor(LCD_COLOR_WHITE);
		BSP_LCD_DisplayStringAt(69, 20, Name, LEFT_MODE);
		xSemaphoreGive(mutex_LCDHandle);

		BSP_TS_GetState(&TS_State);
		if(TS_State.touchDetected != prev_state.touchDetected && TS_State.touchDetected < 2){
			prev_state.touchDetected = TS_State.touchDetected;
			switch (state){
				case 0:
					if(TS_State.touchX[0] >= x+len && TS_State.touchX[0] <= x+Width+len &&
						TS_State.touchY[0] >= y-10 && TS_State.touchY[0] <= y+Height+10){
						state = 1;
					}
					break;

				case 1:
					if(TS_State.touchX[0] >= x+len && TS_State.touchX[0] <= x+Width+len &&
							TS_State.touchY[0] >= y-10 && TS_State.touchY[0] <= y+Height+10){
						state = 0;
						HAL_GPIO_TogglePin(LED2_GPIO_Port, LED2_Pin);
						/* definition and creation of KB */
						osThreadDef(KB, KeyboardTask, osPriorityAboveNormal, 0, 4096);
						KBHandle = osThreadCreate(osThread(KB), NULL);

					} else state = 0;
					break;

//				case 2:
//					if(TS_State.touchY[0] < KEYBOARD_Y) state = 3;
//					break;
//
//				case 3:
//					if(TS_State.touchY[0] < KEYBOARD_Y){
//						state = 0;
//						vTaskDelete(KBHandle);
//						BSP_LCD_SetLayerVisible(1, DISABLE);
//						BSP_LCD_SelectLayer(0);
//					}
//					else state = 2;

				default:
					state = 0;
					break;
			}
		}
		osDelay(100);
	}
  /* USER CODE END InputTask */
}

 /**
  * @brief  Period elapsed callback in non blocking mode
  * @note   This function is called  when TIM6 interrupt took place, inside
  * HAL_TIM_IRQHandler(). It makes a direct call to HAL_IncTick() to increment
  * a global variable "uwTick" used as application time base.
  * @param  htim : TIM handle
  * @retval None
  */
void HAL_TIM_PeriodElapsedCallback(TIM_HandleTypeDef *htim)
{
  if (htim->Instance == TIM6) {
    HAL_IncTick();
  }
}

void Error_Handler(void)
{
  /* USER CODE BEGIN Error_Handler_Debug */
	/* User can add his own implementation to report the HAL error return state */
	__disable_irq();
	BSP_LCD_SetTextColor(LCD_COLOR_RED);
	BSP_LCD_DisplayStringAt(0, 130, (uint8_t *)"ERREUR!", CENTER_MODE);
	while (1)
	{
	}
  /* USER CODE END Error_Handler_Debug */
}

/************************ (C) COPYRIGHT STMicroelectronics *****END OF FILE****/

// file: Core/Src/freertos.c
/* USER CODE BEGIN Header */
/**
  ******************************************************************************
  * File Name          : freertos.c
  * Description        : Code for freertos applications
  ******************************************************************************
  * @attention
  *
  * <h2><center>&copy; Copyright (c) 2021 STMicroelectronics.
  * All rights reserved.</center></h2>
  *
  * This software component is licensed by ST under Ultimate Liberty license
  * SLA0044, the "License"; You may not use this file except in compliance with
  * the License. You may obtain a copy of the License at:
  *                             www.st.com/SLA0044
  *
  ******************************************************************************
  */
/* USER CODE END Header */

#include "FreeRTOS.h"
#include "task.h"
#include "main.h"

/* GetIdleTaskMemory prototype (linked to static allocation support) */
void vApplicationGetIdleTaskMemory( StaticTask_t **ppxIdleTaskTCBBuffer, StackType_t **ppxIdleTaskStackBuffer, uint32_t *pulIdleTaskStackSize );

/* Hook prototypes */
void vApplicationIdleHook(void);
void vApplicationStackOverflowHook(xTaskHandle xTask, signed char *pcTaskName);
void vApplicationMallocFailedHook(void);

/* USER CODE BEGIN 2 */
__weak void vApplicationIdleHook( void )
{
   /* vApplicationIdleHook() will only be called if configUSE_IDLE_HOOK is set
   to 1 in FreeRTOSConfig.h. It will be called on each iteration of the idle
   task. It is essential that code added to this hook function never attempts
   to block in any way (for example, call xQueueReceive() with a block time
   specified, or call vTaskDelay()). If the application makes use of the
   vTaskDelete() API function (as this demo application does) then it is also
   important that vApplicationIdleHook() is permitted to return to its calling
   function, because it is the responsibility of the idle task to clean up
   memory allocated by the kernel to any task that has since been deleted. */
}
/* USER CODE END 2 */

/* USER CODE BEGIN 4 */
__weak void vApplicationStackOverflowHook(xTaskHandle xTask, signed char *pcTaskName)
{
   /* Run time stack overflow checking is performed if
   configCHECK_FOR_STACK_OVERFLOW is defined to 1 or 2. This hook function is
   called if a stack overflow is detected. */
}
/* USER CODE END 4 */

/* USER CODE BEGIN 5 */
__weak void vApplicationMallocFailedHook(void)
{
   /* vApplicationMallocFailedHook() will only be called if
   configUSE_MALLOC_FAILED_HOOK is set to 1 in FreeRTOSConfig.h. It is a hook
   function that will get called if a call to pvPortMalloc() fails.
   pvPortMalloc() is called internally by the kernel whenever a task, queue,
   timer or semaphore is created. It is also called by various parts of the
   demo application. If heap_1.c or heap_2.c are used, then the size of the
   heap available to pvPortMalloc() is defined by configTOTAL_HEAP_SIZE in
   FreeRTOSConfig.h, and the xPortGetFreeHeapSize() API function can be used
   to query the size of free heap space that remains (although it does not
   provide information on how the remaining heap might be fragmented). */
}
/* USER CODE END 5 */

/* USER CODE BEGIN GET_IDLE_TASK_MEMORY */
static StaticTask_t xIdleTaskTCBBuffer;
static StackType_t xIdleStack[configMINIMAL_STACK_SIZE];

void vApplicationGetIdleTaskMemory( StaticTask_t **ppxIdleTaskTCBBuffer, StackType_t **ppxIdleTaskStackBuffer, uint32_t *pulIdleTaskStackSize )
{
  *ppxIdleTaskTCBBuffer = &xIdleTaskTCBBuffer;
  *ppxIdleTaskStackBuffer = &xIdleStack[0];
  *pulIdleTaskStackSize = configMINIMAL_STACK_SIZE;
  /* place for user code */
}
/* USER CODE END GET_IDLE_TASK_MEMORY */

/************************ (C) COPYRIGHT STMicroelectronics *****END OF FILE****/
